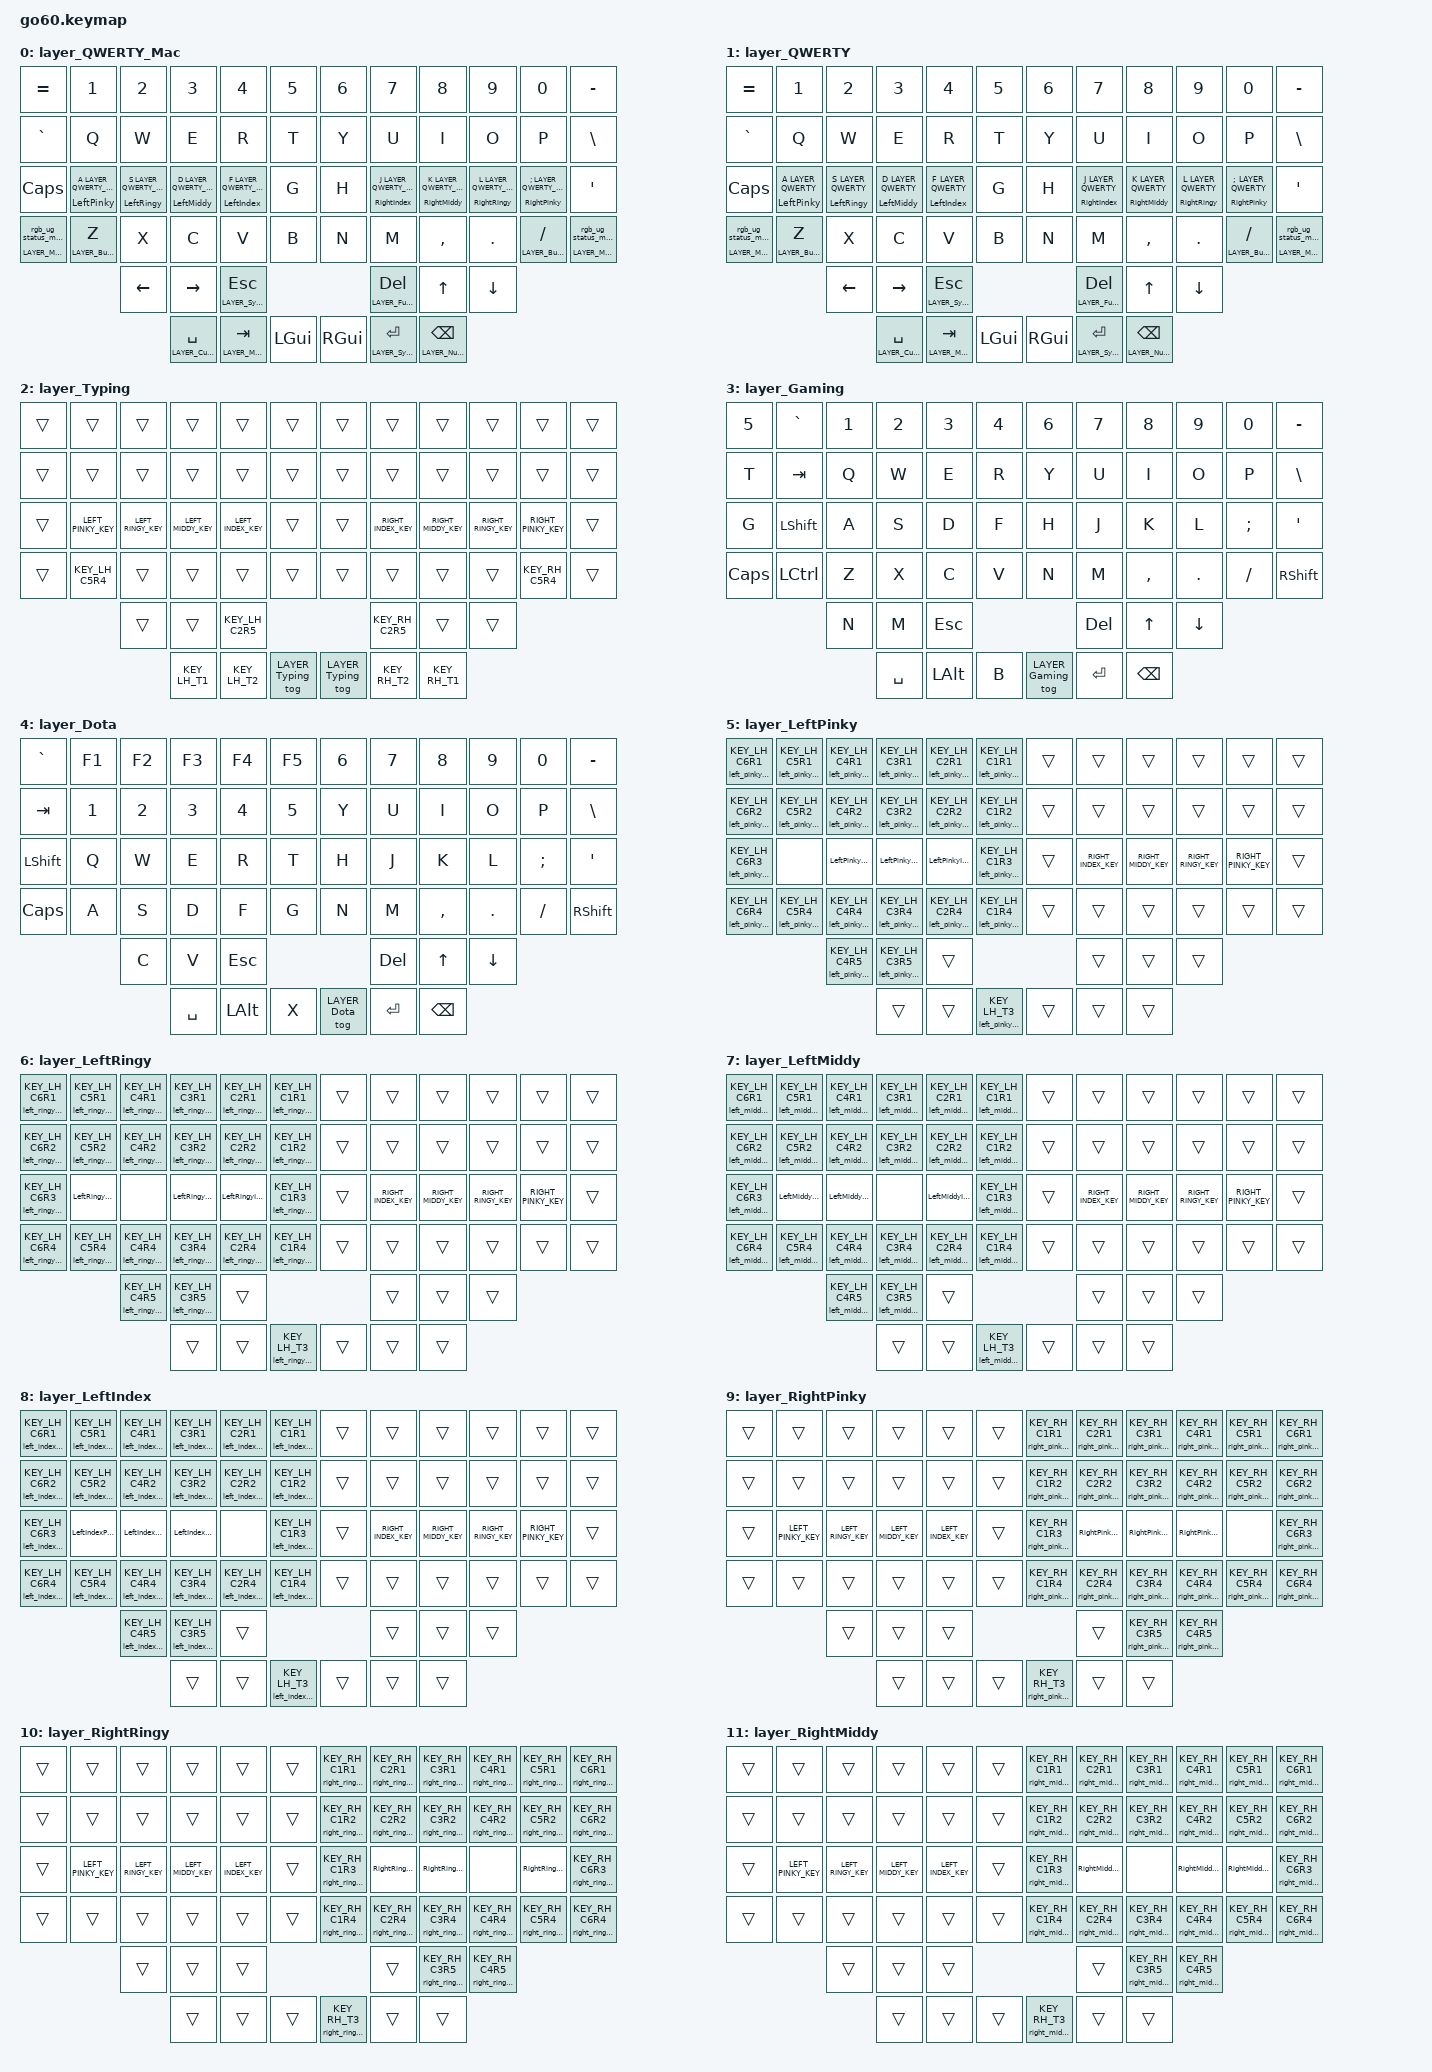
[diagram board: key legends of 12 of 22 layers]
/*
 * Copyright (c) 2020 The ZMK Contributors
 * Copyright (c) 2023 Innaworks Development Limited, trading as MoErgo
 *
 * SPDX-License-Identifier: MIT
 */

#include <behaviors.dtsi>
/* Include all behavior includes needed */
#include <dt-bindings/zmk/outputs.h>
#include <dt-bindings/zmk/keys.h>
#include <dt-bindings/zmk/bt.h>
#include <dt-bindings/zmk/rgb.h>
#include <dt-bindings/zmk/ext_power.h>
#include <dt-bindings/zmk/input_transform.h>
#include <dt-bindings/zmk/pointing.h>

#include <input/processors.dtsi>
#include <zephyr/dt-bindings/input/input-event-codes.h>

/* Helper Macros, based on https://github.com/urob/zmk-helpers/ */

#pragma once

#define ZMK_BEHAVIOR_CORE_tap_dance  \
    compatible = "zmk,behavior-tap-dance"; \
    #binding-cells = <0>

#define ZMK_BEHAVIOR(name, type, ...) \
    name: name { \
        ZMK_BEHAVIOR_CORE_ ## type; \
        __VA_ARGS__ \
    };

#define ZMK_TAP_DANCE(name, ...) \
    ZMK_BEHAVIOR(name, tap_dance, __VA_ARGS__)

#define ZMK_TD_LAYER(name, layer) \
    ZMK_TAP_DANCE(name, \
        tapping-term-ms = <200>; \
        bindings = <&mo layer>, <&to layer>; \
)

/* Environment and metadata defines */
#define KB_TYPE_GLOVE_80 1
#define KB_TYPE_GO_60    2

#define KB_TYPE          KB_TYPE_GO_60

/* Automatically generated layer name #define */
#define LAYER_QWERTY_Mac 0
#define LAYER_QWERTY 1
#define LAYER_Typing 2
#define LAYER_Gaming 3
#define LAYER_Dota 4
#define LAYER_LeftPinky 5
#define LAYER_LeftRingy 6
#define LAYER_LeftMiddy 7
#define LAYER_LeftIndex 8
#define LAYER_RightPinky 9
#define LAYER_RightRingy 10
#define LAYER_RightMiddy 11
#define LAYER_RightIndex 12
#define LAYER_System 13
#define LAYER_Cursor 14
#define LAYER_Mouse 15
#define LAYER_Symbol 16
#define LAYER_Number 17
#define LAYER_Function 18
#define LAYER_Button 19
#define LAYER_Button_Mac 20
#define LAYER_Magic 21

/* To deal with the situation where there is no Lower layer, to keep &lower happy */
#ifndef LAYER_Lower
#define LAYER_Lower 0
#endif

/* Custom Device-tree */
//////////////////////////////////////////////////////////////////////////////
//
// Per-key RGB indicators for layers & mods -- requires PR36 beta firmware:
// override "EXPERIMENTAL_RGB_LAYER" to "y" in Advanced Configuration and
// select "community.pr36.per-key-rgb" from the drop-down menu located at
// Glove80 Layout Editor > Settings > Advanced Settings > Firmware Version
//
// - https://github.com/moergo-sc/zmk/pull/36
// - https://github.com/moergo-sc/zmk/pull/30
// - https://github.com/zmkfirmware/zmk/pull/2752
// - https://dev.glove80.com/#/layout/user/c42ac32d-dc0d-4160-9ee3-fd0fc15f1725
//
//////////////////////////////////////////////////////////////////////////////

#if __has_include(<dt-bindings/zmk/rgb_colors.h>)
  //
  // Color definitions with conflict guard to prevent
  // accidental redefinition of common abbreviations.
  //
  #if defined(RED) || defined(RED_RGB) || \
      defined(COR) || defined(COR_RGB) || \
      defined(ORN) || defined(ORN_RGB) || \
      defined(GDN) || defined(GDN_RGB) || \
      defined(GOL) || defined(GOL_RGB) || \
      defined(YLW) || defined(YLW_RGB) || \
      defined(CHU) || defined(CHU_RGB) || \
      defined(GRN) || defined(GRN_RGB) || \
      defined(SPG) || defined(SPG_RGB) || \
      defined(CYN) || defined(CYN_RGB) || \
      defined(AZU) || defined(AZU_RGB) || \
      defined(TEA) || defined(TEA_RGB) || \
      defined(TUR) || defined(TUR_RGB) || \
      defined(BLU) || defined(BLU_RGB) || \
      defined(PUR) || defined(PUR_RGB) || \
      defined(MAJ) || defined(MAJ_RGB) || \
      defined(PNK) || defined(PNK_RGB) || \
      defined(WHT) || defined(WHT_RGB) || \
      defined(BLK) || defined(BLK_RGB) || \
      defined(___) || \
      defined(DUG) || defined(DUG_RGB) || \
      defined(LAC) || defined(LAC_RGB) || \
      defined(BSL) || defined(BNL) || defined(BCL) || \
      defined(SSL) || defined(SNL) || defined(SCL) || \
      defined(FST) || defined(WRP) || defined(SLO)
  #error "Naming conflict: 3-letter color abbreviation already defined!"
  #endif

  //
  // color definitions from QMK
  // https://github.com/qmk/qmk_firmware/blob/master/quantum/color.h
  //
  #define RED_RGB 0xFF0000 // #FF0000 RED      => RED (red)
  #define COR_RGB 0xFF7C4D // #FF7C4D CORAL    => COR (coral)
  #define ORN_RGB 0xFF8000 // #FF8000 ORANGE   => ORN (ornj)
  #define GDN_RGB 0xD9A521 // #D9A521 GOLDNROD => GDN (gold'nrod)
  #define GOL_RGB 0xFFD900 // #FFD900 GOLD     => GOL (gold)
  #define YLW_RGB 0xFFFF00 // #FFFF00 YELLOW   => YLW (yellow)
  #define CHU_RGB 0x80FF00 // #80FF00 CHARTRSE => CHU (chartreuse)
  #define GRN_RGB 0x00FF00 // #00FF00 GREEN    => GRN (green)
  #define SPG_RGB 0x00FF80 // #00FF80 SPRINGRN => SPG (spring green)
  #define CYN_RGB 0x00FFFF // #00FFFF CYAN     => CYN (sigh-an)
  #define AZU_RGB 0x99F5FF // #99F5FF AZURE    => AZU (a-zur)
  #define TEA_RGB 0x008080 // #008080 TEAL     => TEA (teel)
  #define TUR_RGB 0x476E6A // #476E6A TURQUOIS => TUR (turquoise)
  #define BLU_RGB 0x0000FF // #0000FF BLUE     => BLU (bloo)
  #define PUR_RGB 0x7A00FF // #7A00FF PURPLE   => PUR (purp)
  #define MAJ_RGB 0xFF00FF // #FF00FF MAGENTA  => MAJ (mah-jenta)
  #define PNK_RGB 0xFF80BF // #FF80BF PINK     => PNK (pink)
  #define WHT_RGB 0xFFFFFF // #FFFFFF WHITE    => WHT (white)
  #define BLK_RGB 0x000000 // #000000 BLACK    => BLK (blak)

  //
  // color definitions from MoErgo
  // https://github.com/moergo-sc/zmk/blob/aca523dfce9b6447ffd19d833b791d44f1f286de/app/src/rgb_underglow.c#L259-L265
  //
  #define DUG_RGB 0x00ff68 // #00ff68 DULL_GRN => DUG (dull green)
  #define LAC_RGB 0x6b1fce // #6b1fce LILAC    => LAC (lilac)

  //
  // underglow for the colors above
  //
  #define RED &ug RED_RGB
  #define COR &ug COR_RGB
  #define ORN &ug ORN_RGB
  #define GDN &ug GDN_RGB
  #define GOL &ug GOL_RGB
  #define YLW &ug YLW_RGB
  #define CHU &ug CHU_RGB
  #define GRN &ug GRN_RGB
  #define SPG &ug SPG_RGB
  #define CYN &ug CYN_RGB
  #define AZU &ug AZU_RGB
  #define TEA &ug TEA_RGB
  #define TUR &ug TUR_RGB
  #define BLU &ug BLU_RGB
  #define PUR &ug PUR_RGB
  #define MAJ &ug MAJ_RGB
  #define PNK &ug PNK_RGB
  #define WHT &ug WHT_RGB
  #define BLK &ug BLK_RGB
  #define ___ &ug BLK_RGB
  #define DUG &ug DUG_RGB
  #define LAC &ug LAC_RGB

  //
  // underglow for keyboard locks on the Base layer
  //
  #define BSL &ug_sl LAC_RGB WHT_RGB // ScrollLock COLOR_OFF COLOR_ON
  #define BNL &ug_nl LAC_RGB WHT_RGB // NumLock    COLOR_OFF COLOR_ON
  #define BCL &ug_cl BLK_RGB WHT_RGB // CapsLock   COLOR_OFF COLOR_ON

  //
  // underglow for keyboard locks on the System layer
  //
  #define SSL &ug_sl BLK_RGB WHT_RGB // ScrollLock COLOR_OFF COLOR_ON
  #define SNL &ug_nl BLK_RGB WHT_RGB // NumLock    COLOR_OFF COLOR_ON
  #define SCL &ug_cl BLK_RGB WHT_RGB // CapsLock   COLOR_OFF COLOR_ON

  //
  // colors for mouse speed scaling in Mouse layers
  //
  #define FST GOL
  #define SLO PNK
  #define WRP CHU

  // ==== PER-KEY-RGB <section begins> ====
  / {
    underglow-layer {
      compatible  = "zmk,underglow-layer";

      /*
      Template {
        bindings = <
          ___ ___ ___ ___ ___ ___                   ___ ___ ___ ___ ___ ___
          ___ ___ ___ ___ ___ ___                   ___ ___ ___ ___ ___ ___
          ___ ___ ___ ___ ___ ___                   ___ ___ ___ ___ ___ ___
          ___ ___ ___ ___ ___ ___                   ___ ___ ___ ___ ___ ___
                  ___ ___ ___                           ___ ___ ___
                              ___ ___ ___   ___ ___ ___
        >;
        layer-id = <LAYER_Template>;
      };
      */

      BaseLayer {
        bindings = <
          ___ ___ ___ ___ ___ ___                   ___ ___ ___ ___ ___ ___
          ___ ___ ___ ___ ___ ___                   ___ ___ ___ ___ ___ ___
          ___ MAJ CYN GRN YLW ___                   ___ YLW GRN CYN MAJ ___
          YLW LAC ___ ___ ___ ___                   ___ ___ ___ ___ LAC YLW
                  ___ ___ LAC                           LAC ___ ___
                              BSL BNL BCL   LAC LAC ___
        >;
        layer-id = <0>;
      };

      #ifdef LAYER_QWERTY
      QWERTY {
        bindings = <
          ___ ___ ___ ___ ___ ___                   ___ ___ ___ ___ ___ ___
          ___ ___ ___ ___ RED ___                   ___ ___ ___ ___ ___ ___
          ___ MAJ CYN GRN YLW ___                   ___ YLW GRN CYN MAJ ___
          YLW LAC ___ ___ ___ ___                   ___ ___ ___ ___ LAC YLW
                  ___ ___ RED                           LAC ___ ___
                              BSL BNL BCL   LAC LAC RED
        >;
        layer-id = <LAYER_QWERTY>;
      };
      #endif

      #ifdef LAYER_Typing
      Typing {
        bindings = <
          ___ ___ ___ ___ ___ ___                   ___ ___ ___ ___ ___ ___
          ___ ___ ___ ___ ___ ___                   ___ ___ ___ ___ ___ ___
          ___ ___ ___ ___ ___ ___                   ___ ___ ___ ___ ___ ___
          ___ ___ ___ ___ ___ ___                   ___ ___ ___ ___ ___ ___
                  ___ ___ ___                           ___ ___ ___
                              ___ ___ RED   ___ ___ RED
        >;
        layer-id = <LAYER_Typing>;
      };
      #endif

      #ifdef LAYER_Gaming
      Gaming {
        bindings = <
          GDN GDN GDN GDN GDN GDN                   ___ ___ ___ ___ ___ ___
          GDN GDN GDN AZU GDN GDN                   ___ ___ ___ ___ ___ ___
          GDN YLW AZU AZU AZU GDN                   ___ ___ ___ ___ ___ ___
          SCL GRN GDN GDN GDN GDN                   ___ ___ ___ ___ ___ ___
                  GDN GDN ___                           ___ ___ ___
                              COR CYN COR   ___ ___ RED
        >;
        layer-id = <LAYER_Gaming>;
      };
      #endif

      #ifdef LAYER_Dota
      Dota {
        bindings = <
          GDN GDN GDN GDN GDN GDN                   ___ ___ ___ ___ ___ ___
          COR GDN GDN AZU GDN GDN                   ___ ___ ___ ___ ___ ___
          YLW AZU AZU AZU AZU GDN                   ___ ___ ___ ___ ___ ___
          SCL AZU AZU AZU AZU GDN                   ___ ___ ___ ___ ___ ___
                  GDN GDN ___                           ___ ___ ___
                              COR CYN COR   ___ ___ RED
        >;
        layer-id = <LAYER_Dota>;
      };
      #endif

      #ifdef LAYER_LeftPinky
      LeftPinky {
        bindings = <
          ___ MAJ ___ ___ ___ ___                   ___ ___ ___ ___ ___ ___
          ___ ___ ___ ___ ___ ___                   ___ ___ ___ ___ ___ ___
          ___ MAJ CYN GRN YLW ___                   ___ YLW GRN CYN MAJ ___
          YLW LAC ___ ___ ___ ___                   ___ ___ ___ ___ LAC YLW
                  ___ ___ LAC                           LAC ___ ___
                              BSL BNL BCL   LAC LAC ___
        >;
        layer-id = <LAYER_LeftPinky>;
      };
      #endif

      #ifdef LAYER_LeftRingy
      LeftRingy {
        bindings = <
          ___ ___ CYN ___ ___ ___                   ___ ___ ___ ___ ___ ___
          ___ ___ ___ ___ ___ ___                   ___ ___ ___ ___ ___ ___
          ___ MAJ CYN GRN YLW ___                   ___ YLW GRN CYN MAJ ___
          YLW LAC ___ ___ ___ ___                   ___ ___ ___ ___ LAC YLW
                  ___ ___ LAC                           LAC ___ ___
                              BSL BNL BCL   LAC LAC ___
        >;
        layer-id = <LAYER_LeftRingy>;
      };
      #endif

      #ifdef LAYER_LeftMiddy
      LeftMiddy {
        bindings = <
          ___ ___ ___ GRN ___ ___                   ___ ___ ___ ___ ___ ___
          ___ ___ ___ ___ ___ ___                   ___ ___ ___ ___ ___ ___
          ___ MAJ CYN GRN YLW ___                   ___ YLW GRN CYN MAJ ___
          YLW LAC ___ ___ ___ ___                   ___ ___ ___ ___ LAC YLW
                  ___ ___ LAC                           LAC ___ ___
                              BSL BNL BCL   LAC LAC ___
        >;
        layer-id = <LAYER_LeftMiddy>;
      };
      #endif

      #ifdef LAYER_LeftIndex
      LeftIndex {
        bindings = <
          ___ ___ ___ ___ YLW ___                   ___ ___ ___ ___ ___ ___
          ___ ___ ___ ___ ___ ___                   ___ ___ ___ ___ ___ ___
          ___ MAJ CYN GRN YLW ___                   ___ YLW GRN CYN MAJ ___
          YLW LAC ___ ___ ___ ___                   ___ ___ ___ ___ LAC YLW
                  ___ ___ LAC                           LAC ___ ___
                              BSL BNL BCL   LAC LAC ___
        >;
        layer-id = <LAYER_LeftIndex>;
      };
      #endif

      #ifdef LAYER_RightIndex
      RightIndex {
        bindings = <
          ___ ___ ___ ___ ___ ___                   ___ YLW ___ ___ ___ ___
          ___ ___ ___ ___ ___ ___                   ___ ___ ___ ___ ___ ___
          ___ MAJ CYN GRN YLW ___                   ___ YLW GRN CYN MAJ ___
          YLW LAC ___ ___ ___ ___                   ___ ___ ___ ___ LAC YLW
                  ___ ___ LAC                           LAC ___ ___
                              BSL BNL BCL   LAC LAC ___
        >;
        layer-id = <LAYER_RightIndex>;
      };
      #endif

      #ifdef LAYER_RightMiddy
      RightMiddy {
        bindings = <
          ___ ___ ___ ___ ___ ___                   ___ ___ GRN ___ ___ ___
          ___ ___ ___ ___ ___ ___                   ___ ___ ___ ___ ___ ___
          ___ MAJ CYN GRN YLW ___                   ___ YLW GRN CYN MAJ ___
          YLW LAC ___ ___ ___ ___                   ___ ___ ___ ___ LAC YLW
                  ___ ___ LAC                           LAC ___ ___
                              BSL BNL BCL   LAC LAC ___
        >;
        layer-id = <LAYER_RightMiddy>;
      };
      #endif

      #ifdef LAYER_RightRingy
      RightRingy {
        bindings = <
          ___ ___ ___ ___ ___ ___                   ___ ___ ___ CYN ___ ___
          ___ ___ ___ ___ ___ ___                   ___ ___ ___ ___ ___ ___
          ___ MAJ CYN GRN YLW ___                   ___ YLW GRN CYN MAJ ___
          YLW LAC ___ ___ ___ ___                   ___ ___ ___ ___ LAC YLW
                  ___ ___ LAC                           LAC ___ ___
                              BSL BNL BCL   LAC LAC ___
        >;
        layer-id = <LAYER_RightRingy>;
      };
      #endif

      #ifdef LAYER_RightPinky
      RightPinky {
        bindings = <
          ___ ___ ___ ___ ___ ___                   ___ ___ ___ ___ MAJ ___
          ___ ___ ___ ___ ___ ___                   ___ ___ ___ ___ ___ ___
          ___ MAJ CYN GRN YLW ___                   ___ YLW GRN CYN MAJ ___
          YLW LAC ___ ___ ___ ___                   ___ ___ ___ ___ LAC YLW
                  ___ ___ LAC                           LAC ___ ___
                              BSL BNL BCL   LAC LAC ___
        >;
        layer-id = <LAYER_RightPinky>;
      };
      #endif

      #ifdef LAYER_System
      System {
        bindings = <
          ___ ___ ___ ___ ___ ___                   ___ ___ ___ ___ ___ ___
          ___ PUR COR COR COR PUR                   PNK PNK PNK PNK PNK ___
          ___ MAJ CYN GRN YLW ___                   AZU AZU AZU AZU PNK ___
          ___ SPG SPG COR COR ___                   BLU BLU BLU BLU BLU ___
                  ___ ___ RED                           AZU ___ ___
                              ___ ___ ___   AZU AZU ___
        >;
        layer-id = <LAYER_System>;
      };
      #endif

      #ifdef LAYER_Cursor
      Cursor {
        bindings = <
          ___ ___ ___ ___ ___ ___                   ___ ___ ___ ___ ___ ___
          ___ ___ COR ___ COR ___                   ___ ___ ___ ___ ___ ___
          ___ MAJ CYN GRN YLW ___                   AZU AZU AZU AZU SPG ___
          ___ SPG SPG COR COR ___                   SPG SPG SPG SPG SPG ___
                  ___ ___ ___                           SPG ___ ___
                              RED ___ ___   SPG SPG ___
        >;
        layer-id = <LAYER_Cursor>;
      };
      #endif

      #ifdef LAYER_Mouse
      Mouse {
        bindings = <
          ___ ___ ___ ___ ___ ___                   ___ ___ ___ ___ ___ ___
          ___ ___ COR COR COR ___                   ___ ___ ___ ___ ___ ___
          ___ MAJ CYN GRN YLW ___                   AZU AZU AZU AZU AZU ___
          ___ SPG SPG COR COR ___                   AZU AZU AZU AZU AZU ___
                  ___ ___ ___                           AZU ___ ___
                              ___ RED ___   AZU AZU ___
        >;
        layer-id = <LAYER_Mouse>;
      };
      #endif

      #ifdef LAYER_Function
      Function {
        bindings = <
          ___ ___ ___ ___ ___ ___                   ___ ___ ___ ___ ___ ___
          ___ PNK PNK PNK PNK GDN                   PUR COR COR COR PUR ___
          ___ PNK PNK PNK PNK SSL                   ___ YLW GRN CYN MAJ ___
          ___ PNK PNK PNK PNK GDN                   ___ COR COR SPG SPG ___
                  ___ ___ GDN                           RED ___ ___
                              SPG SPG ___   ___ ___ ___
        >;
        layer-id = <LAYER_Function>;
      };
      #endif

      #ifdef LAYER_Number
      Number {
        bindings = <
          ___ ___ ___ ___ ___ ___                   ___ ___ ___ ___ ___ ___
          ___ SPG GOL GOL GOL SPG                   ___ COR ___ COR ___ ___
          ___ SPG GOL GOL GOL SPG                   ___ YLW GRN CYN MAJ ___
          ___ SPG GOL GOL GOL SPG                   ___ COR COR SPG SPG ___
                  ___ ___ SPG                           ___ ___ ___
                              SPG SPG ___   RED ___ ___
        >;
        layer-id = <LAYER_Number>;
      };
      #endif

      #ifdef LAYER_Symbol
      Symbol {
        bindings = <
          ___ ___ ___ ___ ___ ___                   ___ ___ ___ ___ ___ ___
          ___ SPG SPG SPG SPG SPG                   ___ COR COR COR ___ ___
          ___ SPG SPG SPG SPG SPG                   ___ YLW GRN CYN MAJ ___
          ___ SPG SPG SPG SPG SPG                   ___ COR COR SPG SPG ___
                  ___ ___ SPG                           ___ ___ ___
                              SPG SPG ___   ___ RED ___
        >;
        layer-id = <LAYER_Symbol>;
      };
      #endif

      #ifdef LAYER_Button
      Button {
        bindings = <
          ___ ___ ___ ___ ___ ___                   ___ ___ ___ ___ ___ ___
          ___ ___ GDN ORN ORN ORN                   ORN ORN ORN ORN ___ ___
          ___ MAJ CYN GRN YLW ORN                   ORN YLW GRN CYN MAJ ___
          ___ ORN ORN ORN ORN ORN                   ORN ORN ORN ORN ORN ___
                  ___ ___ COR                           COR ___ ___
                              COR COR ___   COR COR ___
        >;
        layer-id = <LAYER_Button>;
      };
      #endif

      #ifdef LAYER_Button_Mac
      Button_Mac {
        bindings = <
          RED ___ ___ ___ ___ ___                   ___ ___ ___ ___ ___ RED
          ___ ___ GDN ORN ORN ORN                   ORN ORN ORN ORN ___ ___
          ___ MAJ CYN GRN YLW ORN                   ORN YLW GRN CYN MAJ ___
          ___ ORN ORN ORN ORN ORN                   ORN ORN ORN ORN ORN ___
                  ___ ___ COR                           COR ___ ___
                              COR COR ___   COR COR ___
        >;
        layer-id = <LAYER_Button_Mac>;
      };
      #endif
    };
  };
  // ==== PER-KEY-RGB <section ends> =====

  #undef RED
  #undef RED_RGB
  #undef COR
  #undef COR_RGB
  #undef ORN
  #undef ORN_RGB
  #undef GDN
  #undef GDN_RGB
  #undef GOL
  #undef GOL_RGB
  #undef YLW
  #undef YLW_RGB
  #undef CHU
  #undef CHU_RGB
  #undef GRN
  #undef GRN_RGB
  #undef SPG
  #undef SPG_RGB
  #undef CYN
  #undef CYN_RGB
  #undef AZU
  #undef AZU_RGB
  #undef TEA
  #undef TEA_RGB
  #undef TUR
  #undef TUR_RGB
  #undef BLU
  #undef BLU_RGB
  #undef PUR
  #undef PUR_RGB
  #undef MAJ
  #undef MAJ_RGB
  #undef PNK
  #undef PNK_RGB
  #undef WHT
  #undef WHT_RGB
  #undef BLK
  #undef BLK_RGB
  #undef ___
  #undef DUG
  #undef DUG_RGB
  #undef LAC
  #undef LAC_RGB

  #undef BSL
  #undef BNL
  #undef BCL

  #undef SSL
  #undef SNL
  #undef SCL

  #undef FST
  #undef WRP
  #undef SLO
#endif

/* Glove80 system behavior & macros */
/ {
    input_processors {
        zip_click_to_right_click_mapper: zip_click_to_right_click_mapper {
            compatible = "zmk,input-processor-code-mapper";
            #input-processor-cells = <0>;
            type = <INPUT_EV_KEY>;
            map = <INPUT_BTN_0 INPUT_BTN_1>;
        };
    };

    behaviors {
        ZMK_TD_LAYER(lower, LAYER_Lower)

        magic: magic {
            compatible = "zmk,behavior-hold-tap";
            label = "MAGIC_HOLD_TAP";
            #binding-cells = <2>;
            flavor = "tap-preferred";
            tapping-term-ms = <200>;
            bindings = <&mo>, <&rgb_ug_status_macro>;
        };
    };

    macros {
        rgb_ug_status_macro: rgb_ug_status_macro {
            label = "RGB_UG_STATUS";
            compatible = "zmk,behavior-macro";
            #binding-cells = <0>;
            bindings
                = <&rgb_ug RGB_STATUS>;
        };
    };
};


/ {
#ifdef BT_DISC_CMD
    behaviors {
        bt_0: bt_0 {
            compatible = "zmk,behavior-tap-dance";
            label = "BT_0";
            #binding-cells = <0>;
            tapping-term-ms = <200>;
            bindings = <&bt_select_0>, <&bt BT_DISC 0>;
        };
        bt_1: bt_1 {
            compatible = "zmk,behavior-tap-dance";
            label = "BT_1";
            #binding-cells = <0>;
            tapping-term-ms = <200>;
            bindings = <&bt_select_1>, <&bt BT_DISC 1>;
        };
        bt_2: bt_2 {
            compatible = "zmk,behavior-tap-dance";
            label = "BT_2";
            #binding-cells = <0>;
            tapping-term-ms = <200>;
            bindings = <&bt_select_2>, <&bt BT_DISC 2>;
        };
        bt_3: bt_3 {
            compatible = "zmk,behavior-tap-dance";
            label = "BT_3";
            #binding-cells = <0>;
            tapping-term-ms = <200>;
            bindings = <&bt_select_3>, <&bt BT_DISC 3>;
        };
    };
    macros {
        bt_select_0: bt_select_0 {
            label = "BT_SELECT_0";
            compatible = "zmk,behavior-macro";
            #binding-cells = <0>;
            bindings
                = <&out OUT_BLE>,
                  <&bt BT_SEL 0>;
        };
        bt_select_1: bt_select_1 {
            label = "BT_SELECT_1";
            compatible = "zmk,behavior-macro";
            #binding-cells = <0>;
            bindings
                = <&out OUT_BLE>,
                  <&bt BT_SEL 1>;
        };
        bt_select_2: bt_select_2 {
            label = "BT_SELECT_2";
            compatible = "zmk,behavior-macro";
            #binding-cells = <0>;
            bindings
                = <&out OUT_BLE>,
                  <&bt BT_SEL 2>;
        };
        bt_select_3: bt_select_3 {
            label = "BT_SELECT_3";
            compatible = "zmk,behavior-macro";
            #binding-cells = <0>;
            bindings
                = <&out OUT_BLE>,
                  <&bt BT_SEL 3>;
        };
    };
#else
    macros {
        bt_0: bt_0 {
            label = "BT_0";
            compatible = "zmk,behavior-macro";
            #binding-cells = <0>;
            bindings
                = <&out OUT_BLE>,
                  <&bt BT_SEL 0>;
        };
        bt_1: bt_1 {
            label = "BT_1";
            compatible = "zmk,behavior-macro";
            #binding-cells = <0>;
            bindings
                = <&out OUT_BLE>,
                  <&bt BT_SEL 1>;
        };
        bt_2: bt_2 {
            label = "BT_2";
            compatible = "zmk,behavior-macro";
            #binding-cells = <0>;
            bindings
                = <&out OUT_BLE>,
                  <&bt BT_SEL 2>;
        };
        bt_3: bt_3 {
            label = "BT_3";
            compatible = "zmk,behavior-macro";
            #binding-cells = <0>;
            bindings
                = <&out OUT_BLE>,
                  <&bt BT_SEL 3>;
        };
    };
#endif
};

/ {
    behaviors {
    };
};

/* Key positions */
#define POS_LH_C6R1 0
#define POS_LH_C5R1 1
#define POS_LH_C4R1 2
#define POS_LH_C3R1 3
#define POS_LH_C2R1 4
#define POS_LH_C1R1 5
#define POS_RH_C1R1 6
#define POS_RH_C2R1 7
#define POS_RH_C3R1 8
#define POS_RH_C4R1 9
#define POS_RH_C5R1 10
#define POS_RH_C6R1 11
#define POS_LH_C6R2 12
#define POS_LH_C5R2 13
#define POS_LH_C4R2 14
#define POS_LH_C3R2 15
#define POS_LH_C2R2 16
#define POS_LH_C1R2 17
#define POS_RH_C1R2 18
#define POS_RH_C2R2 19
#define POS_RH_C3R2 20
#define POS_RH_C4R2 21
#define POS_RH_C5R2 22
#define POS_RH_C6R2 23
#define POS_LH_C6R3 24
#define POS_LH_C5R3 25
#define POS_LH_C4R3 26
#define POS_LH_C3R3 27
#define POS_LH_C2R3 28
#define POS_LH_C1R3 29
#define POS_RH_C1R3 30
#define POS_RH_C2R3 31
#define POS_RH_C3R3 32
#define POS_RH_C4R3 33
#define POS_RH_C5R3 34
#define POS_RH_C6R3 35
#define POS_LH_C6R4 36
#define POS_LH_C5R4 37
#define POS_LH_C4R4 38
#define POS_LH_C3R4 39
#define POS_LH_C2R4 40
#define POS_LH_C1R4 41
#define POS_RH_C1R4 42
#define POS_RH_C2R4 43
#define POS_RH_C3R4 44
#define POS_RH_C4R4 45
#define POS_RH_C5R4 46
#define POS_RH_C6R4 47
#define POS_LH_C4R5 48
#define POS_LH_C3R5 49
#define POS_LH_C2R5 50
#define POS_RH_C2R5 51
#define POS_RH_C3R5 52
#define POS_RH_C4R5 53
#define POS_LH_T1 54
#define POS_LH_T2 55
#define POS_LH_T3 56
#define POS_RH_T3 57
#define POS_RH_T2 58
#define POS_RH_T1 59

/* Custom Defined Behaviors */
/ {
// NOTE: Use the many #define settings below to customize this keymap!
#define DIFFICULTY_LEVEL  0  // 0:custom, 1:easy -> 5:hard (see below)
#define ENFORCE_BILATERAL    // cancels single-handed home row mod+tap
#define SPACE_FORGIVENESS    // allow lingering taps on the space bar
// TIP: Add more setting overrides here instead of editing them below.

//////////////////////////////////////////////////////////////////////////////
//
// Sunaku's Keymap v41 -- "Glorious Engrammer"
// - https://github.com/sunaku/glove80-keymaps
//
//////////////////////////////////////////////////////////////////////////////

//
// OPERATING_SYSTEM defines which operating system you intend to use
// with this keymap, because shortcuts vary across operating systems.
//
// - https://zmk.dev/docs/codes
// - https://en.wikipedia.org/wiki/Table_of_keyboard_shortcuts
//
// This setting also affects the UNICODE() function defined below, as
// each OS has different shortcuts for typing Unicode hex characters.
//
// NOTE: You may need to enable Unicode hexadecimal input in your OS:
// - (macOS) https://uknowit.uwgb.edu/page.php?id=22623
//     and   https://github.com/ldanet/unicode-hex-input-fix
// - (Linux) https://help.ubuntu.com/stable/ubuntu-help/tips-specialchars.html.en#ctrlshiftu
// - (Windows) https://github.com/samhocevar/wincompose
//
// Specifically, Windows users should be running the WinCompose tool,
// which lets you type Unicode characters via hexadecimal codepoints.
//
// Windows/Linux Def
#define _C      LC
#define _REDO   _C(Y)
#define _UNDO   _C(Z)
#define _CUT    _C(X)
#define _COPY   _C(C)
#define _PASTE  _C(V)
#define _FIND   _C(F)
// Mac Def
#define _C_Mac      LG
#define _REDO_Mac   _C_Mac(LS(Z))
#define _HOME_Mac   _C_Mac(LEFT)
#define _END_Mac    _C_Mac(RIGHT)
#define _UNDO_Mac   _C_Mac(Z)
#define _CUT_Mac    _C_Mac(X)
#define _COPY_Mac   _C_Mac(C)
#define _PASTE_Mac  _C_Mac(V)
#define _FIND_Mac   _C_Mac(F)
#define _PSCRN_Mac  _C_Mac(LS(N4))

//
// Keymap specific knowledge of the base layer's alpha + ZMK layout
//
#define KEY_LH_C6R1 EQUAL
#define KEY_LH_C5R1 N1
#define KEY_LH_C4R1 N2
#define KEY_LH_C3R1 N3
#define KEY_LH_C2R1 N4
#define KEY_LH_C1R1 N5
#define KEY_RH_C1R1 N6
#define KEY_RH_C2R1 N7
#define KEY_RH_C3R1 N8
#define KEY_RH_C4R1 N9
#define KEY_RH_C5R1 N0
#define KEY_RH_C6R1 MINUS
#define KEY_LH_C6R2 GRAVE
#define KEY_LH_C5R2 Q
#define KEY_LH_C4R2 W
#define KEY_LH_C3R2 E
#define KEY_LH_C2R2 R
#define KEY_LH_C1R2 T
#define KEY_RH_C1R2 Y
#define KEY_RH_C2R2 U
#define KEY_RH_C3R2 I
#define KEY_RH_C4R2 O
#define KEY_RH_C5R2 P
#define KEY_RH_C6R2 BSLH
#define KEY_LH_C6R3 CAPS
#define KEY_LH_C5R3 A
#define KEY_LH_C4R3 S
#define KEY_LH_C3R3 D
#define KEY_LH_C2R3 F
#define KEY_LH_C1R3 G
#define KEY_RH_C1R3 H
#define KEY_RH_C2R3 J
#define KEY_RH_C3R3 K
#define KEY_RH_C4R3 L
#define KEY_RH_C5R3 SEMI
#define KEY_RH_C6R3 SQT
#define KEY_LH_C6R4 LSFT
#define KEY_LH_C5R4 Z
#define KEY_LH_C4R4 X
#define KEY_LH_C3R4 C
#define KEY_LH_C2R4 V
#define KEY_LH_C1R4 B
#define KEY_RH_C1R4 N
#define KEY_RH_C2R4 M
#define KEY_RH_C3R4 COMMA
#define KEY_RH_C4R4 DOT
#define KEY_RH_C5R4 FSLH
#define KEY_RH_C6R4 RSFT
#define KEY_LH_C4R5 LEFT
#define KEY_LH_C3R5 RIGHT
#define KEY_LH_C2R5 ESC
#define KEY_RH_C2R5 DELETE
#define KEY_RH_C3R5 UP
#define KEY_RH_C4R5 DOWN
#define KEY_LH_T1 SPACE
#define KEY_LH_T2 TAB
#define KEY_LH_T3 LALT
#define KEY_RH_T3 RALT
#define KEY_RH_T2 ENTER
#define KEY_RH_T1 BSPC

combos {};

behaviors {

  //////////////////////////////////////////////////////////////////////////
  //
  // Miryoku layers and home row mods (ported from my QMK endgame)
  // - https://sunaku.github.io/home-row-mods.html#porting-to-zmk
  // - https://github.com/urob/zmk-config#timeless-homerow-mods
  //
  //////////////////////////////////////////////////////////////////////////

  //
  // DIFFICULTY_LEVEL specifies your level of expertise with this keymap.
  // It's meant to help newcomers gradually work their way up to mastery.
  //
  // #define DIFFICULTY_LEVEL 1 // novice (500ms)
  // #define DIFFICULTY_LEVEL 2 // slower (400ms)
  // #define DIFFICULTY_LEVEL 3 // normal (300ms)
  // #define DIFFICULTY_LEVEL 4 // faster (200ms)
  // #define DIFFICULTY_LEVEL 5 // expert (100ms)
  //
  // You can disable this setting by omitting it or assigning a `0` zero,
  // in which case it will default to my personal set of time thresholds.
  //
  // #define DIFFICULTY_LEVEL 0 // sunaku (150ms)
  //
  // No matter what difficulty level you choose, you can always override
  // any settings in this keymap at the beginning of this configuration.
  //
  #ifdef DIFFICULTY_LEVEL
    #if DIFFICULTY_LEVEL > 0 && DIFFICULTY_LEVEL < 6
      #ifndef TAPPING_RESOLUTION
        #define TAPPING_RESOLUTION ((6 - DIFFICULTY_LEVEL) * 100)
      #endif
    #endif
  #endif

  //
  // TAPPING_RESOLUTION specifies the maximum speed at which the keyboard
  // confuses your taps as being holds when you type on home row mod keys.
  // When you lower this value, the same confusion should still occur; but
  // when you raise this value, you should be able to type normally again.
  //
  #ifndef TAPPING_RESOLUTION
  #define TAPPING_RESOLUTION 150
  #endif

  //
  // ENFORCE_BILATERAL cancels out single-handed home row mods activation by
  // releasing any currently pressed mods and replacing them with plain taps.
  //
  // NOTE: You may still encounter "flashing mods" where an operating system
  // action is triggered by the release of mods, such as LGUI which launches
  // the Windows Start Menu and LALT which opens the Microsoft Office Ribbon.
  //
  //#define ENFORCE_BILATERAL

  //
  // SPACE_FORGIVENESS taps when the symbol layer access key is merely held
  // and released, without any symbol been tapped while the access was held.
  // For example, suppose you hold the symbol layer key and, before pressing
  // another key, you suddenly decide that you don't want the layer anymore:
  //
  // <1> If this setting is enabled, the underlying tap behavior is triggered
  //     to type a single character when you release that layer access key.
  //
  // <2> Otherwise, nothing happens when you release that layer access key.
  //
  // NOTE: This setting interferes with (and effectively disables) per-key
  // RGB indicators (PR30) for layers accessed via thumb layer access keys.
  //
  //#define SPACE_FORGIVENESS

  //
  // The *_FINGER_MOD specify which modifiers are used by home row mod keys.
  // Here, we use Miryoku's "GACS" (Win, Alt, Ctrl, Shift) order by default.
  //
  #ifndef PINKY_FINGER_MOD
  #define PINKY_FINGER_MOD LGUI
  #endif
  #ifndef RINGY_FINGER_MOD
  #define RINGY_FINGER_MOD LALT
  #endif
  #ifndef MIDDY_FINGER_MOD
  #define MIDDY_FINGER_MOD LCTL
  #endif
  #ifndef INDEX_FINGER_MOD
  #define INDEX_FINGER_MOD LSFT
  #endif
  //
  // The following settings let you configure mods individually, per finger:
  //
  #ifndef LEFT_PINKY_MOD
  #define LEFT_PINKY_MOD PINKY_FINGER_MOD
  #endif
  #ifndef RIGHT_PINKY_MOD
  #define RIGHT_PINKY_MOD PINKY_FINGER_MOD
  #endif
  #ifndef LEFT_RINGY_MOD
  #define LEFT_RINGY_MOD RINGY_FINGER_MOD
  #endif
  #ifndef RIGHT_RINGY_MOD
  #define RIGHT_RINGY_MOD RINGY_FINGER_MOD
  #endif
  #ifndef LEFT_MIDDY_MOD
  #define LEFT_MIDDY_MOD MIDDY_FINGER_MOD
  #endif
  #ifndef RIGHT_MIDDY_MOD
  #define RIGHT_MIDDY_MOD MIDDY_FINGER_MOD
  #endif
  #ifndef LEFT_INDEX_MOD
  #define LEFT_INDEX_MOD INDEX_FINGER_MOD
  #endif
  #ifndef RIGHT_INDEX_MOD
  #define RIGHT_INDEX_MOD INDEX_FINGER_MOD
  #endif

  //
  // HOMEY_HOLDING_TYPE defines the flavor of ZMK hold-tap behavior to use
  // for the pinky, ring, and middle fingers (which are assigned to Super,
  // Alt, and Ctrl respectively in the Miryoku system) on home row keys.
  //
  #ifndef HOMEY_HOLDING_TYPE
  #define HOMEY_HOLDING_TYPE "tap-preferred"
  #endif

  //
  // HOMEY_HOLDING_TIME defines how long you need to hold (milliseconds)
  // home row mod keys in order to send their modifiers to the computer
  // (i.e. "register" them) for mod-click mouse usage (e.g. Ctrl-Click).
  //
  #ifndef HOMEY_HOLDING_TIME
  #define HOMEY_HOLDING_TIME (TAPPING_RESOLUTION + 90)
  #endif
  #ifndef INDEX_HOLDING_TIME
  #define INDEX_HOLDING_TIME (TAPPING_RESOLUTION + 20)
  #endif
  #ifndef MIDDY_HOLDING_TIME
  #define MIDDY_HOLDING_TIME (TAPPING_RESOLUTION + 60)
  #endif
  #ifndef RINGY_HOLDING_TIME
  #define RINGY_HOLDING_TIME (TAPPING_RESOLUTION + 90)
  #endif
  #ifndef PINKY_HOLDING_TIME
  #define PINKY_HOLDING_TIME (TAPPING_RESOLUTION + 110)
  #endif

  //
  // HOMEY_STREAK_DECAY defines how long you need to wait (milliseconds)
  // after typing before you can use home row mods again.  It prevents
  // unintended activation of home row mods when you're actively typing.
  //
  #ifndef HOMEY_STREAK_DECAY
  #define HOMEY_STREAK_DECAY TAPPING_RESOLUTION
  #endif

  //
  // HOMEY_REPEAT_DECAY defines how much time you have left (milliseconds)
  // after tapping a key to hold it again in order to make it auto-repeat.
  //
  #ifndef HOMEY_REPEAT_DECAY
  #define HOMEY_REPEAT_DECAY (TAPPING_RESOLUTION + 150)
  #endif // "tap then hold" for key auto-repeat

  //
  // CHORD_HOLDING_TYPE defines the flavor of ZMK hold-tap behavior to use
  // for chorded home row mods (secondary keypresses in multi-mod chords).
  //
  #ifndef CHORD_HOLDING_TYPE
  #define CHORD_HOLDING_TYPE HOMEY_HOLDING_TYPE
  #endif

  //
  // CHORD_HOLDING_TIME defines how long you need to hold (milliseconds)
  // home row mod keys in order to send their modifiers to the computer
  // (i.e. "register" them) for mod-click mouse usage (e.g. Ctrl-Click).
  // This is specifically for secondary keypresses in multi-mod chords.
  //
  #ifndef CHORD_HOLDING_TIME
  #define CHORD_HOLDING_TIME TAPPING_RESOLUTION
  #endif

  //
  // CHORD_STREAK_DECAY defines how long you need to wait (milliseconds)
  // after typing before you can use home row mods again.  It prevents
  // unintended activation of home row mods when you're actively typing
  // This is specifically for secondary keypresses in multi-mod chords.
  //
  #ifndef CHORD_STREAK_DECAY
  #define CHORD_STREAK_DECAY HOMEY_STREAK_DECAY
  #endif

  //
  // CHORD_REPEAT_DECAY defines how much time you have left (milliseconds)
  // after tapping a key to hold it again in order to make it auto-repeat.
  // This is specifically for secondary keypresses in multi-mod chords.
  //
  #ifndef CHORD_REPEAT_DECAY
  #define CHORD_REPEAT_DECAY HOMEY_REPEAT_DECAY
  #endif

  //
  // INDEX_HOLDING_TYPE defines the flavor of ZMK hold-tap behavior to use
  // for index fingers (which Miryoku assigns to Shift) on home row keys.
  //
  // NOTE: The "tap-preferred" flavor of ZMK hold-tap for index finger keys
  // allows faster activation of the Shift modifier (without having to wait
  // for the modified key to be released as the "balanced" flavor requires).
  //
  #ifndef INDEX_HOLDING_TYPE
  #define INDEX_HOLDING_TYPE "tap-preferred"
  #endif

  //
  // INDEX_STREAK_DECAY defines how long you need to wait (milliseconds)
  // after typing before you can use home row mods again.  It prevents
  // unintended activation of home row mods when you're actively typing.
  //
  #ifndef INDEX_STREAK_DECAY
  #define INDEX_STREAK_DECAY (TAPPING_RESOLUTION - 50)
  #endif

  //
  // INDEX_REPEAT_DECAY defines how much time you have left (milliseconds)
  // after tapping a key to hold it again in order to make it auto-repeat.
  //
  #ifndef INDEX_REPEAT_DECAY
  #define INDEX_REPEAT_DECAY (TAPPING_RESOLUTION + 150)
  #endif // "tap then hold" for key auto-repeat

  //
  // PLAIN_HOLDING_TYPE defines the flavor of ZMK hold-tap behavior to use
  // for index fingers (which Miryoku assigns to Shift) on home row keys.
  //
  // NOTE: The "tap-preferred" flavor of ZMK hold-tap for index finger keys
  // allows faster activation of the Shift modifier (without having to wait
  // for the modified key to be released as the "balanced" flavor requires).
  //
  #ifndef PLAIN_HOLDING_TYPE
  #define PLAIN_HOLDING_TYPE INDEX_HOLDING_TYPE
  #endif

  //
  // PLAIN_HOLDING_TIME defines how long you need to hold (milliseconds)
  // index finger keys in order to send their modifiers to the computer
  // (i.e. "register" them) for mod-click mouse usage (e.g. Shift-Click).
  //
  #ifndef PLAIN_HOLDING_TIME
  #define PLAIN_HOLDING_TIME (TAPPING_RESOLUTION + 50)
  #endif

  //
  // PLAIN_STREAK_DECAY defines how long you need to wait (milliseconds)
  // after typing before you can use home row mods again.  It prevents
  // unintended activation of home row mods when you're actively typing.
  //
  #ifndef PLAIN_STREAK_DECAY
  #define PLAIN_STREAK_DECAY HOMEY_STREAK_DECAY
  #endif

  //
  // PLAIN_REPEAT_DECAY defines how much time you have left (milliseconds)
  // after tapping a key to hold it again in order to make it auto-repeat.
  //
  #ifndef PLAIN_REPEAT_DECAY
  #define PLAIN_REPEAT_DECAY (TAPPING_RESOLUTION + 150)
  #endif // "tap then hold" for key auto-repeat

  //
  // THUMB_HOLDING_TYPE defines the flavor of ZMK hold-tap behavior to use
  // for the thumbs (which are assigned to 6 layers in the Miryoku system).
  //
  // NOTE: The "balanced" flavor of ZMK hold-tap provides instant modifier
  // activation for the symbol layer (if the tapped symbol key is released
  // while the thumb layer key is still held down) for quicker programming.
  //
  #ifndef THUMB_HOLDING_TYPE
  #define THUMB_HOLDING_TYPE "balanced"
  #endif

  //
  // THUMB_HOLDING_TIME defines how long you need to hold (milliseconds)
  // a thumb key to activate a layer.  Shorter holds are treated as taps.
  //
  #ifndef THUMB_HOLDING_TIME
  #define THUMB_HOLDING_TIME (TAPPING_RESOLUTION + 50)
  #endif

  //
  // THUMB_REPEAT_DECAY defines how much time you have left (milliseconds)
  // after tapping a key to hold it again in order to make it auto-repeat.
  //
  #ifndef THUMB_REPEAT_DECAY
  #define THUMB_REPEAT_DECAY (TAPPING_RESOLUTION + 150)
  #endif // "tap then hold" for key auto-repeat

  //
  // SPACE_HOLDING_TYPE defines the flavor of ZMK hold-tap behavior to use
  // for spacebar (assigned to the right thumb's home position by default).
  //
  #ifndef SPACE_HOLDING_TYPE
  #define SPACE_HOLDING_TYPE THUMB_HOLDING_TYPE
  #endif

  //
  // SPACE_HOLDING_TIME defines how long you need to hold (milliseconds)
  // the space thumb key to activate.  Shorter holds are treated as taps.
  //
  #ifndef SPACE_HOLDING_TIME
  #define SPACE_HOLDING_TIME (TAPPING_RESOLUTION + 20)
  #endif

  //
  // SPACE_REPEAT_DECAY defines how much time you have left (milliseconds)
  // after tapping a key to hold it again in order to make it auto-repeat.
  //
  #ifndef SPACE_REPEAT_DECAY
  #define SPACE_REPEAT_DECAY TAPPING_RESOLUTION
  #endif

  //
  // Go60 key positions index for positional hold-tap
  // - https://discord.com/channels/877392805654306816/937645688244826154/1066713913351221248
  // - https://media.discordapp.net/attachments/937645688244826154/1066713913133121556/image.png
  //
  // |-------------------------|-------------------------|
  // | LEFT_HAND_KEYS          |         RIGHT_HAND_KEYS |
  // |                         |                         |
  // |  0  1  2  3  4  5       |        6  7  8  9 10 11 |
  // | 12 13 14 15 16 17       |       18 19 20 21 22 23 |
  // | 24 25 26 27 28 29       |       30 31 32 33 34 35 |
  // | 36 37 38 39 40 41       |       42 43 44 45 46 47 |
  // |       48 49 50          |          51 52 53       |
  // |                54 55 56 | 57 58 59                |
  // |-------------------------|-------------------------|
  //
  #define LEFT_HAND_KEYS       \
        0  1  2  3  4  5       \
       12 13 14 15 16 17       \
       24 25 26 27 28 29       \
       36 37 38 39 40 41       \
             48 49 50
  #define RIGHT_HAND_KEYS      \
                                        6  7  8  9 10 11 \
                                       18 19 20 21 22 23 \
                                       30 31 32 33 34 35 \
                                       42 43 44 45 46 47 \
                                          51 52 53
  #define THUMB_KEYS           \
                      54 55 56   57 58 59

  #define LEFT_PINKY_KEY  KEY_LH_C5R3
  #define LEFT_RINGY_KEY  KEY_LH_C4R3
  #define LEFT_MIDDY_KEY  KEY_LH_C3R3
  #define LEFT_INDEX_KEY  KEY_LH_C2R3

  #define RIGHT_PINKY_KEY KEY_RH_C5R3
  #define RIGHT_RINGY_KEY KEY_RH_C4R3
  #define RIGHT_MIDDY_KEY KEY_RH_C3R3
  #define RIGHT_INDEX_KEY KEY_RH_C2R3

  //
  // Home row mods with bilateral combinations support
  //
  #ifndef PINKY_HOLDING_TYPE
  #define PINKY_HOLDING_TYPE HOMEY_HOLDING_TYPE
  #endif
  #ifndef PINKY_CHORD_HOLDING_TYPE
  #define PINKY_CHORD_HOLDING_TYPE CHORD_HOLDING_TYPE
  #endif
  #ifndef LEFT_PINKY_CHORD_HOLDING_TYPE
  #define LEFT_PINKY_CHORD_HOLDING_TYPE PINKY_CHORD_HOLDING_TYPE
  #endif
  #ifndef RIGHT_PINKY_CHORD_HOLDING_TYPE
  #define RIGHT_PINKY_CHORD_HOLDING_TYPE PINKY_CHORD_HOLDING_TYPE
  #endif
  #ifndef PINKY_HOLDING_TIME
  #define PINKY_HOLDING_TIME HOMEY_HOLDING_TIME
  #endif
  #ifndef PINKY_CHORD_HOLDING_TIME
  #define PINKY_CHORD_HOLDING_TIME CHORD_HOLDING_TIME
  #endif
  #ifndef LEFT_PINKY_CHORD_HOLDING_TIME
  #define LEFT_PINKY_CHORD_HOLDING_TIME PINKY_CHORD_HOLDING_TIME
  #endif
  #ifndef RIGHT_PINKY_CHORD_HOLDING_TIME
  #define RIGHT_PINKY_CHORD_HOLDING_TIME PINKY_CHORD_HOLDING_TIME
  #endif
  #ifndef PINKY_STREAK_DECAY
  #define PINKY_STREAK_DECAY HOMEY_STREAK_DECAY
  #endif
  #ifndef PINKY_CHORD_STREAK_DECAY
  #define PINKY_CHORD_STREAK_DECAY CHORD_STREAK_DECAY
  #endif
  #ifndef LEFT_PINKY_CHORD_STREAK_DECAY
  #define LEFT_PINKY_CHORD_STREAK_DECAY PINKY_CHORD_STREAK_DECAY
  #endif
  #ifndef RIGHT_PINKY_CHORD_STREAK_DECAY
  #define RIGHT_PINKY_CHORD_STREAK_DECAY PINKY_CHORD_STREAK_DECAY
  #endif
  #ifndef PINKY_REPEAT_DECAY
  #define PINKY_REPEAT_DECAY HOMEY_REPEAT_DECAY
  #endif
  #ifndef PINKY_CHORD_REPEAT_DECAY
  #define PINKY_CHORD_REPEAT_DECAY CHORD_REPEAT_DECAY
  #endif
  #ifndef LEFT_PINKY_CHORD_REPEAT_DECAY
  #define LEFT_PINKY_CHORD_REPEAT_DECAY PINKY_CHORD_REPEAT_DECAY
  #endif
  #ifndef RIGHT_PINKY_CHORD_REPEAT_DECAY
  #define RIGHT_PINKY_CHORD_REPEAT_DECAY PINKY_CHORD_REPEAT_DECAY
  #endif
  #ifndef RINGY_HOLDING_TYPE
  #define RINGY_HOLDING_TYPE HOMEY_HOLDING_TYPE
  #endif
  #ifndef RINGY_CHORD_HOLDING_TYPE
  #define RINGY_CHORD_HOLDING_TYPE CHORD_HOLDING_TYPE
  #endif
  #ifndef LEFT_RINGY_CHORD_HOLDING_TYPE
  #define LEFT_RINGY_CHORD_HOLDING_TYPE RINGY_CHORD_HOLDING_TYPE
  #endif
  #ifndef RIGHT_RINGY_CHORD_HOLDING_TYPE
  #define RIGHT_RINGY_CHORD_HOLDING_TYPE RINGY_CHORD_HOLDING_TYPE
  #endif
  #ifndef RINGY_HOLDING_TIME
  #define RINGY_HOLDING_TIME HOMEY_HOLDING_TIME
  #endif
  #ifndef RINGY_CHORD_HOLDING_TIME
  #define RINGY_CHORD_HOLDING_TIME CHORD_HOLDING_TIME
  #endif
  #ifndef LEFT_RINGY_CHORD_HOLDING_TIME
  #define LEFT_RINGY_CHORD_HOLDING_TIME RINGY_CHORD_HOLDING_TIME
  #endif
  #ifndef RIGHT_RINGY_CHORD_HOLDING_TIME
  #define RIGHT_RINGY_CHORD_HOLDING_TIME RINGY_CHORD_HOLDING_TIME
  #endif
  #ifndef RINGY_STREAK_DECAY
  #define RINGY_STREAK_DECAY HOMEY_STREAK_DECAY
  #endif
  #ifndef RINGY_CHORD_STREAK_DECAY
  #define RINGY_CHORD_STREAK_DECAY CHORD_STREAK_DECAY
  #endif
  #ifndef LEFT_RINGY_CHORD_STREAK_DECAY
  #define LEFT_RINGY_CHORD_STREAK_DECAY RINGY_CHORD_STREAK_DECAY
  #endif
  #ifndef RIGHT_RINGY_CHORD_STREAK_DECAY
  #define RIGHT_RINGY_CHORD_STREAK_DECAY RINGY_CHORD_STREAK_DECAY
  #endif
  #ifndef RINGY_REPEAT_DECAY
  #define RINGY_REPEAT_DECAY HOMEY_REPEAT_DECAY
  #endif
  #ifndef RINGY_CHORD_REPEAT_DECAY
  #define RINGY_CHORD_REPEAT_DECAY CHORD_REPEAT_DECAY
  #endif
  #ifndef LEFT_RINGY_CHORD_REPEAT_DECAY
  #define LEFT_RINGY_CHORD_REPEAT_DECAY RINGY_CHORD_REPEAT_DECAY
  #endif
  #ifndef RIGHT_RINGY_CHORD_REPEAT_DECAY
  #define RIGHT_RINGY_CHORD_REPEAT_DECAY RINGY_CHORD_REPEAT_DECAY
  #endif
  #ifndef MIDDY_HOLDING_TYPE
  #define MIDDY_HOLDING_TYPE HOMEY_HOLDING_TYPE
  #endif
  #ifndef MIDDY_CHORD_HOLDING_TYPE
  #define MIDDY_CHORD_HOLDING_TYPE CHORD_HOLDING_TYPE
  #endif
  #ifndef LEFT_MIDDY_CHORD_HOLDING_TYPE
  #define LEFT_MIDDY_CHORD_HOLDING_TYPE MIDDY_CHORD_HOLDING_TYPE
  #endif
  #ifndef RIGHT_MIDDY_CHORD_HOLDING_TYPE
  #define RIGHT_MIDDY_CHORD_HOLDING_TYPE MIDDY_CHORD_HOLDING_TYPE
  #endif
  #ifndef MIDDY_HOLDING_TIME
  #define MIDDY_HOLDING_TIME HOMEY_HOLDING_TIME
  #endif
  #ifndef MIDDY_CHORD_HOLDING_TIME
  #define MIDDY_CHORD_HOLDING_TIME CHORD_HOLDING_TIME
  #endif
  #ifndef LEFT_MIDDY_CHORD_HOLDING_TIME
  #define LEFT_MIDDY_CHORD_HOLDING_TIME MIDDY_CHORD_HOLDING_TIME
  #endif
  #ifndef RIGHT_MIDDY_CHORD_HOLDING_TIME
  #define RIGHT_MIDDY_CHORD_HOLDING_TIME MIDDY_CHORD_HOLDING_TIME
  #endif
  #ifndef MIDDY_STREAK_DECAY
  #define MIDDY_STREAK_DECAY HOMEY_STREAK_DECAY
  #endif
  #ifndef MIDDY_CHORD_STREAK_DECAY
  #define MIDDY_CHORD_STREAK_DECAY CHORD_STREAK_DECAY
  #endif
  #ifndef LEFT_MIDDY_CHORD_STREAK_DECAY
  #define LEFT_MIDDY_CHORD_STREAK_DECAY MIDDY_CHORD_STREAK_DECAY
  #endif
  #ifndef RIGHT_MIDDY_CHORD_STREAK_DECAY
  #define RIGHT_MIDDY_CHORD_STREAK_DECAY MIDDY_CHORD_STREAK_DECAY
  #endif
  #ifndef MIDDY_REPEAT_DECAY
  #define MIDDY_REPEAT_DECAY HOMEY_REPEAT_DECAY
  #endif
  #ifndef MIDDY_CHORD_REPEAT_DECAY
  #define MIDDY_CHORD_REPEAT_DECAY CHORD_REPEAT_DECAY
  #endif
  #ifndef LEFT_MIDDY_CHORD_REPEAT_DECAY
  #define LEFT_MIDDY_CHORD_REPEAT_DECAY MIDDY_CHORD_REPEAT_DECAY
  #endif
  #ifndef RIGHT_MIDDY_CHORD_REPEAT_DECAY
  #define RIGHT_MIDDY_CHORD_REPEAT_DECAY MIDDY_CHORD_REPEAT_DECAY
  #endif
  #ifndef INDEX_HOLDING_TYPE
  #define INDEX_HOLDING_TYPE HOMEY_HOLDING_TYPE
  #endif
  #ifndef INDEX_CHORD_HOLDING_TYPE
  #define INDEX_CHORD_HOLDING_TYPE CHORD_HOLDING_TYPE
  #endif
  #ifndef LEFT_INDEX_CHORD_HOLDING_TYPE
  #define LEFT_INDEX_CHORD_HOLDING_TYPE INDEX_CHORD_HOLDING_TYPE
  #endif
  #ifndef RIGHT_INDEX_CHORD_HOLDING_TYPE
  #define RIGHT_INDEX_CHORD_HOLDING_TYPE INDEX_CHORD_HOLDING_TYPE
  #endif
  #ifndef INDEX_HOLDING_TIME
  #define INDEX_HOLDING_TIME HOMEY_HOLDING_TIME
  #endif
  #ifndef INDEX_CHORD_HOLDING_TIME
  #define INDEX_CHORD_HOLDING_TIME CHORD_HOLDING_TIME
  #endif
  #ifndef LEFT_INDEX_CHORD_HOLDING_TIME
  #define LEFT_INDEX_CHORD_HOLDING_TIME INDEX_CHORD_HOLDING_TIME
  #endif
  #ifndef RIGHT_INDEX_CHORD_HOLDING_TIME
  #define RIGHT_INDEX_CHORD_HOLDING_TIME INDEX_CHORD_HOLDING_TIME
  #endif
  #ifndef INDEX_STREAK_DECAY
  #define INDEX_STREAK_DECAY HOMEY_STREAK_DECAY
  #endif
  #ifndef INDEX_CHORD_STREAK_DECAY
  #define INDEX_CHORD_STREAK_DECAY CHORD_STREAK_DECAY
  #endif
  #ifndef LEFT_INDEX_CHORD_STREAK_DECAY
  #define LEFT_INDEX_CHORD_STREAK_DECAY INDEX_CHORD_STREAK_DECAY
  #endif
  #ifndef RIGHT_INDEX_CHORD_STREAK_DECAY
  #define RIGHT_INDEX_CHORD_STREAK_DECAY INDEX_CHORD_STREAK_DECAY
  #endif
  #ifndef INDEX_REPEAT_DECAY
  #define INDEX_REPEAT_DECAY HOMEY_REPEAT_DECAY
  #endif
  #ifndef INDEX_CHORD_REPEAT_DECAY
  #define INDEX_CHORD_REPEAT_DECAY CHORD_REPEAT_DECAY
  #endif
  #ifndef LEFT_INDEX_CHORD_REPEAT_DECAY
  #define LEFT_INDEX_CHORD_REPEAT_DECAY INDEX_CHORD_REPEAT_DECAY
  #endif
  #ifndef RIGHT_INDEX_CHORD_REPEAT_DECAY
  #define RIGHT_INDEX_CHORD_REPEAT_DECAY INDEX_CHORD_REPEAT_DECAY
  #endif
  #ifndef LEFT_PINKY_HOLDING_TYPE
  #define LEFT_PINKY_HOLDING_TYPE PINKY_HOLDING_TYPE
  #endif
  #ifndef LEFT_PINKY_HOLDING_TIME
  #define LEFT_PINKY_HOLDING_TIME PINKY_HOLDING_TIME
  #endif
  #ifndef LEFT_PINKY_STREAK_DECAY
  #define LEFT_PINKY_STREAK_DECAY PINKY_STREAK_DECAY
  #endif
  #ifndef LEFT_PINKY_REPEAT_DECAY
  #define LEFT_PINKY_REPEAT_DECAY PINKY_REPEAT_DECAY
  #endif
  left_pinky: homey_left_pinky {
    compatible = "zmk,behavior-hold-tap";
    flavor = LEFT_PINKY_HOLDING_TYPE;
    hold-trigger-key-positions = <RIGHT_HAND_KEYS THUMB_KEYS>;
    hold-trigger-on-release; // wait for other home row mods
    tapping-term-ms = <LEFT_PINKY_HOLDING_TIME>;
    quick-tap-ms = <LEFT_PINKY_REPEAT_DECAY>;
    require-prior-idle-ms = <LEFT_PINKY_STREAK_DECAY>;
    #binding-cells = <2>;
    bindings = <&kp>, <&kp>;
  };
  left_pinky_bilateral: homey_left_pinky_bilateral {
    compatible = "zmk,behavior-hold-tap";
    flavor = LEFT_PINKY_HOLDING_TYPE;
    hold-trigger-key-positions = <RIGHT_HAND_KEYS THUMB_KEYS>;
    hold-trigger-on-release; // wait for other home row mods
    tapping-term-ms = <LEFT_PINKY_HOLDING_TIME>;
    quick-tap-ms = <LEFT_PINKY_REPEAT_DECAY>;
    require-prior-idle-ms = <LEFT_PINKY_STREAK_DECAY>;
    #binding-cells = <2>;
    bindings = <&left_pinky_hold>, <&kp>;
  };
  left_pinky_hold: homey_left_pinky_hold {
    compatible = "zmk,behavior-macro-one-param";
    wait-ms = <0>;
    tap-ms = <0>;
    #binding-cells = <1>;
    bindings
      = <&macro_param_1to1>
      , <&macro_press &kp MACRO_PLACEHOLDER>
      #ifdef LAYER_LeftPinky
      , <&macro_press &mo LAYER_LeftPinky>
      #endif
      , <&macro_pause_for_release>
      , <&macro_param_1to1>
      , <&macro_release &kp MACRO_PLACEHOLDER>
      #ifdef LAYER_LeftPinky
      , <&macro_release &mo LAYER_LeftPinky>
      #endif
      ;
  };
  left_pinky_tap: homey_left_pinky_tap {
    compatible = "zmk,behavior-macro-one-param";
    wait-ms = <0>;
    tap-ms = <0>;
    #binding-cells = <1>;
    bindings
      = <&macro_release
          &kp LSFT &kp RSFT
          &kp LALT &kp RALT
          &kp LCTL &kp RCTL
          &kp LGUI &kp RGUI>
      , <&macro_tap &kp LEFT_PINKY_KEY>
      , <&macro_param_1to1>
      , <&macro_tap &kp MACRO_PLACEHOLDER>
      ;
  };
  #define LeftPinky(key, layer_index) LeftPinky_unroll(layer_index) (key)
  #define LeftPinky_unroll(layer_index) LeftPinky_concat(LeftPinky_layer, layer_index)
  #define LeftPinky_concat(prefix, layer_index) prefix ## layer_index
  #ifdef ENFORCE_BILATERAL
  #define left_pinky_layer0_variant left_pinky_bilateral
  #else
  #define left_pinky_layer0_variant left_pinky
  #endif
  #define LeftPinky_layer0(key) left_pinky_layer0_variant LEFT_PINKY_MOD key
  #define LeftPinky_layer1(key) left_pinky LEFT_PINKY_MOD key
  #define LeftPinky_layer2(key) left_pinky LEFT_PINKY_MOD key
  #define LeftPinky_layer3(key) left_pinky LEFT_PINKY_MOD key
  #define LeftPinky_layer4(key) left_pinky LEFT_PINKY_MOD key
  #define LeftPinky_layer5(key) left_pinky LEFT_PINKY_MOD key
  #define LeftPinky_layer6(key) left_pinky LEFT_PINKY_MOD key
  #define LeftPinky_layer7(key) left_pinky LEFT_PINKY_MOD key
  #ifndef RIGHT_PINKY_HOLDING_TYPE
  #define RIGHT_PINKY_HOLDING_TYPE PINKY_HOLDING_TYPE
  #endif
  #ifndef RIGHT_PINKY_HOLDING_TIME
  #define RIGHT_PINKY_HOLDING_TIME PINKY_HOLDING_TIME
  #endif
  #ifndef RIGHT_PINKY_STREAK_DECAY
  #define RIGHT_PINKY_STREAK_DECAY PINKY_STREAK_DECAY
  #endif
  #ifndef RIGHT_PINKY_REPEAT_DECAY
  #define RIGHT_PINKY_REPEAT_DECAY PINKY_REPEAT_DECAY
  #endif
  right_pinky: homey_right_pinky {
    compatible = "zmk,behavior-hold-tap";
    flavor = RIGHT_PINKY_HOLDING_TYPE;
    hold-trigger-key-positions = <LEFT_HAND_KEYS THUMB_KEYS>;
    hold-trigger-on-release; // wait for other home row mods
    tapping-term-ms = <RIGHT_PINKY_HOLDING_TIME>;
    quick-tap-ms = <RIGHT_PINKY_REPEAT_DECAY>;
    require-prior-idle-ms = <RIGHT_PINKY_STREAK_DECAY>;
    #binding-cells = <2>;
    bindings = <&kp>, <&kp>;
  };
  right_pinky_bilateral: homey_right_pinky_bilateral {
    compatible = "zmk,behavior-hold-tap";
    flavor = RIGHT_PINKY_HOLDING_TYPE;
    hold-trigger-key-positions = <LEFT_HAND_KEYS THUMB_KEYS>;
    hold-trigger-on-release; // wait for other home row mods
    tapping-term-ms = <RIGHT_PINKY_HOLDING_TIME>;
    quick-tap-ms = <RIGHT_PINKY_REPEAT_DECAY>;
    require-prior-idle-ms = <RIGHT_PINKY_STREAK_DECAY>;
    #binding-cells = <2>;
    bindings = <&right_pinky_hold>, <&kp>;
  };
  right_pinky_hold: homey_right_pinky_hold {
    compatible = "zmk,behavior-macro-one-param";
    wait-ms = <0>;
    tap-ms = <0>;
    #binding-cells = <1>;
    bindings
      = <&macro_param_1to1>
      , <&macro_press &kp MACRO_PLACEHOLDER>
      #ifdef LAYER_RightPinky
      , <&macro_press &mo LAYER_RightPinky>
      #endif
      , <&macro_pause_for_release>
      , <&macro_param_1to1>
      , <&macro_release &kp MACRO_PLACEHOLDER>
      #ifdef LAYER_RightPinky
      , <&macro_release &mo LAYER_RightPinky>
      #endif
      ;
  };
  right_pinky_tap: homey_right_pinky_tap {
    compatible = "zmk,behavior-macro-one-param";
    wait-ms = <0>;
    tap-ms = <0>;
    #binding-cells = <1>;
    bindings
      = <&macro_release
          &kp LSFT &kp RSFT
          &kp LALT &kp RALT
          &kp LCTL &kp RCTL
          &kp LGUI &kp RGUI>
      , <&macro_tap &kp RIGHT_PINKY_KEY>
      , <&macro_param_1to1>
      , <&macro_tap &kp MACRO_PLACEHOLDER>
      ;
  };
  #define RightPinky(key, layer_index) RightPinky_unroll(layer_index) (key)
  #define RightPinky_unroll(layer_index) RightPinky_concat(RightPinky_layer, layer_index)
  #define RightPinky_concat(prefix, layer_index) prefix ## layer_index
  #ifdef ENFORCE_BILATERAL
  #define right_pinky_layer0_variant right_pinky_bilateral
  #else
  #define right_pinky_layer0_variant right_pinky
  #endif
  #define RightPinky_layer0(key) right_pinky_layer0_variant RIGHT_PINKY_MOD key
  #define RightPinky_layer1(key) right_pinky RIGHT_PINKY_MOD key
  #define RightPinky_layer2(key) right_pinky RIGHT_PINKY_MOD key
  #define RightPinky_layer3(key) right_pinky RIGHT_PINKY_MOD key
  #define RightPinky_layer4(key) right_pinky RIGHT_PINKY_MOD key
  #define RightPinky_layer5(key) right_pinky RIGHT_PINKY_MOD key
  #define RightPinky_layer6(key) right_pinky RIGHT_PINKY_MOD key
  #define RightPinky_layer7(key) right_pinky RIGHT_PINKY_MOD key
  #ifndef LEFT_RINGY_HOLDING_TYPE
  #define LEFT_RINGY_HOLDING_TYPE RINGY_HOLDING_TYPE
  #endif
  #ifndef LEFT_RINGY_HOLDING_TIME
  #define LEFT_RINGY_HOLDING_TIME RINGY_HOLDING_TIME
  #endif
  #ifndef LEFT_RINGY_STREAK_DECAY
  #define LEFT_RINGY_STREAK_DECAY RINGY_STREAK_DECAY
  #endif
  #ifndef LEFT_RINGY_REPEAT_DECAY
  #define LEFT_RINGY_REPEAT_DECAY RINGY_REPEAT_DECAY
  #endif
  left_ringy: homey_left_ringy {
    compatible = "zmk,behavior-hold-tap";
    flavor = LEFT_RINGY_HOLDING_TYPE;
    hold-trigger-key-positions = <RIGHT_HAND_KEYS THUMB_KEYS>;
    hold-trigger-on-release; // wait for other home row mods
    tapping-term-ms = <LEFT_RINGY_HOLDING_TIME>;
    quick-tap-ms = <LEFT_RINGY_REPEAT_DECAY>;
    require-prior-idle-ms = <LEFT_RINGY_STREAK_DECAY>;
    #binding-cells = <2>;
    bindings = <&kp>, <&kp>;
  };
  left_ringy_bilateral: homey_left_ringy_bilateral {
    compatible = "zmk,behavior-hold-tap";
    flavor = LEFT_RINGY_HOLDING_TYPE;
    hold-trigger-key-positions = <RIGHT_HAND_KEYS THUMB_KEYS>;
    hold-trigger-on-release; // wait for other home row mods
    tapping-term-ms = <LEFT_RINGY_HOLDING_TIME>;
    quick-tap-ms = <LEFT_RINGY_REPEAT_DECAY>;
    require-prior-idle-ms = <LEFT_RINGY_STREAK_DECAY>;
    #binding-cells = <2>;
    bindings = <&left_ringy_hold>, <&kp>;
  };
  left_ringy_hold: homey_left_ringy_hold {
    compatible = "zmk,behavior-macro-one-param";
    wait-ms = <0>;
    tap-ms = <0>;
    #binding-cells = <1>;
    bindings
      = <&macro_param_1to1>
      , <&macro_press &kp MACRO_PLACEHOLDER>
      #ifdef LAYER_LeftRingy
      , <&macro_press &mo LAYER_LeftRingy>
      #endif
      , <&macro_pause_for_release>
      , <&macro_param_1to1>
      , <&macro_release &kp MACRO_PLACEHOLDER>
      #ifdef LAYER_LeftRingy
      , <&macro_release &mo LAYER_LeftRingy>
      #endif
      ;
  };
  left_ringy_tap: homey_left_ringy_tap {
    compatible = "zmk,behavior-macro-one-param";
    wait-ms = <0>;
    tap-ms = <0>;
    #binding-cells = <1>;
    bindings
      = <&macro_release
          &kp LSFT &kp RSFT
          &kp LALT &kp RALT
          &kp LCTL &kp RCTL
          &kp LGUI &kp RGUI>
      , <&macro_tap &kp LEFT_RINGY_KEY>
      , <&macro_param_1to1>
      , <&macro_tap &kp MACRO_PLACEHOLDER>
      ;
  };
  #define LeftRingy(key, layer_index) LeftRingy_unroll(layer_index) (key)
  #define LeftRingy_unroll(layer_index) LeftRingy_concat(LeftRingy_layer, layer_index)
  #define LeftRingy_concat(prefix, layer_index) prefix ## layer_index
  #ifdef ENFORCE_BILATERAL
  #define left_ringy_layer0_variant left_ringy_bilateral
  #else
  #define left_ringy_layer0_variant left_ringy
  #endif
  #define LeftRingy_layer0(key) left_ringy_layer0_variant LEFT_RINGY_MOD key
  #define LeftRingy_layer1(key) left_ringy LEFT_RINGY_MOD key
  #define LeftRingy_layer2(key) left_ringy LEFT_RINGY_MOD key
  #define LeftRingy_layer3(key) left_ringy LEFT_RINGY_MOD key
  #define LeftRingy_layer4(key) left_ringy LEFT_RINGY_MOD key
  #define LeftRingy_layer5(key) left_ringy LEFT_RINGY_MOD key
  #define LeftRingy_layer6(key) left_ringy LEFT_RINGY_MOD key
  #define LeftRingy_layer7(key) left_ringy LEFT_RINGY_MOD key
  #ifndef RIGHT_RINGY_HOLDING_TYPE
  #define RIGHT_RINGY_HOLDING_TYPE RINGY_HOLDING_TYPE
  #endif
  #ifndef RIGHT_RINGY_HOLDING_TIME
  #define RIGHT_RINGY_HOLDING_TIME RINGY_HOLDING_TIME
  #endif
  #ifndef RIGHT_RINGY_STREAK_DECAY
  #define RIGHT_RINGY_STREAK_DECAY RINGY_STREAK_DECAY
  #endif
  #ifndef RIGHT_RINGY_REPEAT_DECAY
  #define RIGHT_RINGY_REPEAT_DECAY RINGY_REPEAT_DECAY
  #endif
  right_ringy: homey_right_ringy {
    compatible = "zmk,behavior-hold-tap";
    flavor = RIGHT_RINGY_HOLDING_TYPE;
    hold-trigger-key-positions = <LEFT_HAND_KEYS THUMB_KEYS>;
    hold-trigger-on-release; // wait for other home row mods
    tapping-term-ms = <RIGHT_RINGY_HOLDING_TIME>;
    quick-tap-ms = <RIGHT_RINGY_REPEAT_DECAY>;
    require-prior-idle-ms = <RIGHT_RINGY_STREAK_DECAY>;
    #binding-cells = <2>;
    bindings = <&kp>, <&kp>;
  };
  right_ringy_bilateral: homey_right_ringy_bilateral {
    compatible = "zmk,behavior-hold-tap";
    flavor = RIGHT_RINGY_HOLDING_TYPE;
    hold-trigger-key-positions = <LEFT_HAND_KEYS THUMB_KEYS>;
    hold-trigger-on-release; // wait for other home row mods
    tapping-term-ms = <RIGHT_RINGY_HOLDING_TIME>;
    quick-tap-ms = <RIGHT_RINGY_REPEAT_DECAY>;
    require-prior-idle-ms = <RIGHT_RINGY_STREAK_DECAY>;
    #binding-cells = <2>;
    bindings = <&right_ringy_hold>, <&kp>;
  };
  right_ringy_hold: homey_right_ringy_hold {
    compatible = "zmk,behavior-macro-one-param";
    wait-ms = <0>;
    tap-ms = <0>;
    #binding-cells = <1>;
    bindings
      = <&macro_param_1to1>
      , <&macro_press &kp MACRO_PLACEHOLDER>
      #ifdef LAYER_RightRingy
      , <&macro_press &mo LAYER_RightRingy>
      #endif
      , <&macro_pause_for_release>
      , <&macro_param_1to1>
      , <&macro_release &kp MACRO_PLACEHOLDER>
      #ifdef LAYER_RightRingy
      , <&macro_release &mo LAYER_RightRingy>
      #endif
      ;
  };
  right_ringy_tap: homey_right_ringy_tap {
    compatible = "zmk,behavior-macro-one-param";
    wait-ms = <0>;
    tap-ms = <0>;
    #binding-cells = <1>;
    bindings
      = <&macro_release
          &kp LSFT &kp RSFT
          &kp LALT &kp RALT
          &kp LCTL &kp RCTL
          &kp LGUI &kp RGUI>
      , <&macro_tap &kp RIGHT_RINGY_KEY>
      , <&macro_param_1to1>
      , <&macro_tap &kp MACRO_PLACEHOLDER>
      ;
  };
  #define RightRingy(key, layer_index) RightRingy_unroll(layer_index) (key)
  #define RightRingy_unroll(layer_index) RightRingy_concat(RightRingy_layer, layer_index)
  #define RightRingy_concat(prefix, layer_index) prefix ## layer_index
  #ifdef ENFORCE_BILATERAL
  #define right_ringy_layer0_variant right_ringy_bilateral
  #else
  #define right_ringy_layer0_variant right_ringy
  #endif
  #define RightRingy_layer0(key) right_ringy_layer0_variant RIGHT_RINGY_MOD key
  #define RightRingy_layer1(key) right_ringy RIGHT_RINGY_MOD key
  #define RightRingy_layer2(key) right_ringy RIGHT_RINGY_MOD key
  #define RightRingy_layer3(key) right_ringy RIGHT_RINGY_MOD key
  #define RightRingy_layer4(key) right_ringy RIGHT_RINGY_MOD key
  #define RightRingy_layer5(key) right_ringy RIGHT_RINGY_MOD key
  #define RightRingy_layer6(key) right_ringy RIGHT_RINGY_MOD key
  #define RightRingy_layer7(key) right_ringy RIGHT_RINGY_MOD key
  #ifndef LEFT_MIDDY_HOLDING_TYPE
  #define LEFT_MIDDY_HOLDING_TYPE MIDDY_HOLDING_TYPE
  #endif
  #ifndef LEFT_MIDDY_HOLDING_TIME
  #define LEFT_MIDDY_HOLDING_TIME MIDDY_HOLDING_TIME
  #endif
  #ifndef LEFT_MIDDY_STREAK_DECAY
  #define LEFT_MIDDY_STREAK_DECAY MIDDY_STREAK_DECAY
  #endif
  #ifndef LEFT_MIDDY_REPEAT_DECAY
  #define LEFT_MIDDY_REPEAT_DECAY MIDDY_REPEAT_DECAY
  #endif
  left_middy: homey_left_middy {
    compatible = "zmk,behavior-hold-tap";
    flavor = LEFT_MIDDY_HOLDING_TYPE;
    hold-trigger-key-positions = <RIGHT_HAND_KEYS THUMB_KEYS>;
    hold-trigger-on-release; // wait for other home row mods
    tapping-term-ms = <LEFT_MIDDY_HOLDING_TIME>;
    quick-tap-ms = <LEFT_MIDDY_REPEAT_DECAY>;
    require-prior-idle-ms = <LEFT_MIDDY_STREAK_DECAY>;
    #binding-cells = <2>;
    bindings = <&kp>, <&kp>;
  };
  left_middy_bilateral: homey_left_middy_bilateral {
    compatible = "zmk,behavior-hold-tap";
    flavor = LEFT_MIDDY_HOLDING_TYPE;
    hold-trigger-key-positions = <RIGHT_HAND_KEYS THUMB_KEYS>;
    hold-trigger-on-release; // wait for other home row mods
    tapping-term-ms = <LEFT_MIDDY_HOLDING_TIME>;
    quick-tap-ms = <LEFT_MIDDY_REPEAT_DECAY>;
    require-prior-idle-ms = <LEFT_MIDDY_STREAK_DECAY>;
    #binding-cells = <2>;
    bindings = <&left_middy_hold>, <&kp>;
  };
  left_middy_hold: homey_left_middy_hold {
    compatible = "zmk,behavior-macro-one-param";
    wait-ms = <0>;
    tap-ms = <0>;
    #binding-cells = <1>;
    bindings
      = <&macro_param_1to1>
      , <&macro_press &kp MACRO_PLACEHOLDER>
      #ifdef LAYER_LeftMiddy
      , <&macro_press &mo LAYER_LeftMiddy>
      #endif
      , <&macro_pause_for_release>
      , <&macro_param_1to1>
      , <&macro_release &kp MACRO_PLACEHOLDER>
      #ifdef LAYER_LeftMiddy
      , <&macro_release &mo LAYER_LeftMiddy>
      #endif
      ;
  };
  left_middy_tap: homey_left_middy_tap {
    compatible = "zmk,behavior-macro-one-param";
    wait-ms = <0>;
    tap-ms = <0>;
    #binding-cells = <1>;
    bindings
      = <&macro_release
          &kp LSFT &kp RSFT
          &kp LALT &kp RALT
          &kp LCTL &kp RCTL
          &kp LGUI &kp RGUI>
      , <&macro_tap &kp LEFT_MIDDY_KEY>
      , <&macro_param_1to1>
      , <&macro_tap &kp MACRO_PLACEHOLDER>
      ;
  };
  #define LeftMiddy(key, layer_index) LeftMiddy_unroll(layer_index) (key)
  #define LeftMiddy_unroll(layer_index) LeftMiddy_concat(LeftMiddy_layer, layer_index)
  #define LeftMiddy_concat(prefix, layer_index) prefix ## layer_index
  #ifdef ENFORCE_BILATERAL
  #define left_middy_layer0_variant left_middy_bilateral
  #else
  #define left_middy_layer0_variant left_middy
  #endif
  #define LeftMiddy_layer0(key) left_middy_layer0_variant LEFT_MIDDY_MOD key
  #define LeftMiddy_layer1(key) left_middy LEFT_MIDDY_MOD key
  #define LeftMiddy_layer2(key) left_middy LEFT_MIDDY_MOD key
  #define LeftMiddy_layer3(key) left_middy LEFT_MIDDY_MOD key
  #define LeftMiddy_layer4(key) left_middy LEFT_MIDDY_MOD key
  #define LeftMiddy_layer5(key) left_middy LEFT_MIDDY_MOD key
  #define LeftMiddy_layer6(key) left_middy LEFT_MIDDY_MOD key
  #define LeftMiddy_layer7(key) left_middy LEFT_MIDDY_MOD key
  #ifndef RIGHT_MIDDY_HOLDING_TYPE
  #define RIGHT_MIDDY_HOLDING_TYPE MIDDY_HOLDING_TYPE
  #endif
  #ifndef RIGHT_MIDDY_HOLDING_TIME
  #define RIGHT_MIDDY_HOLDING_TIME MIDDY_HOLDING_TIME
  #endif
  #ifndef RIGHT_MIDDY_STREAK_DECAY
  #define RIGHT_MIDDY_STREAK_DECAY MIDDY_STREAK_DECAY
  #endif
  #ifndef RIGHT_MIDDY_REPEAT_DECAY
  #define RIGHT_MIDDY_REPEAT_DECAY MIDDY_REPEAT_DECAY
  #endif
  right_middy: homey_right_middy {
    compatible = "zmk,behavior-hold-tap";
    flavor = RIGHT_MIDDY_HOLDING_TYPE;
    hold-trigger-key-positions = <LEFT_HAND_KEYS THUMB_KEYS>;
    hold-trigger-on-release; // wait for other home row mods
    tapping-term-ms = <RIGHT_MIDDY_HOLDING_TIME>;
    quick-tap-ms = <RIGHT_MIDDY_REPEAT_DECAY>;
    require-prior-idle-ms = <RIGHT_MIDDY_STREAK_DECAY>;
    #binding-cells = <2>;
    bindings = <&kp>, <&kp>;
  };
  right_middy_bilateral: homey_right_middy_bilateral {
    compatible = "zmk,behavior-hold-tap";
    flavor = RIGHT_MIDDY_HOLDING_TYPE;
    hold-trigger-key-positions = <LEFT_HAND_KEYS THUMB_KEYS>;
    hold-trigger-on-release; // wait for other home row mods
    tapping-term-ms = <RIGHT_MIDDY_HOLDING_TIME>;
    quick-tap-ms = <RIGHT_MIDDY_REPEAT_DECAY>;
    require-prior-idle-ms = <RIGHT_MIDDY_STREAK_DECAY>;
    #binding-cells = <2>;
    bindings = <&right_middy_hold>, <&kp>;
  };
  right_middy_hold: homey_right_middy_hold {
    compatible = "zmk,behavior-macro-one-param";
    wait-ms = <0>;
    tap-ms = <0>;
    #binding-cells = <1>;
    bindings
      = <&macro_param_1to1>
      , <&macro_press &kp MACRO_PLACEHOLDER>
      #ifdef LAYER_RightMiddy
      , <&macro_press &mo LAYER_RightMiddy>
      #endif
      , <&macro_pause_for_release>
      , <&macro_param_1to1>
      , <&macro_release &kp MACRO_PLACEHOLDER>
      #ifdef LAYER_RightMiddy
      , <&macro_release &mo LAYER_RightMiddy>
      #endif
      ;
  };
  right_middy_tap: homey_right_middy_tap {
    compatible = "zmk,behavior-macro-one-param";
    wait-ms = <0>;
    tap-ms = <0>;
    #binding-cells = <1>;
    bindings
      = <&macro_release
          &kp LSFT &kp RSFT
          &kp LALT &kp RALT
          &kp LCTL &kp RCTL
          &kp LGUI &kp RGUI>
      , <&macro_tap &kp RIGHT_MIDDY_KEY>
      , <&macro_param_1to1>
      , <&macro_tap &kp MACRO_PLACEHOLDER>
      ;
  };
  #define RightMiddy(key, layer_index) RightMiddy_unroll(layer_index) (key)
  #define RightMiddy_unroll(layer_index) RightMiddy_concat(RightMiddy_layer, layer_index)
  #define RightMiddy_concat(prefix, layer_index) prefix ## layer_index
  #ifdef ENFORCE_BILATERAL
  #define right_middy_layer0_variant right_middy_bilateral
  #else
  #define right_middy_layer0_variant right_middy
  #endif
  #define RightMiddy_layer0(key) right_middy_layer0_variant RIGHT_MIDDY_MOD key
  #define RightMiddy_layer1(key) right_middy RIGHT_MIDDY_MOD key
  #define RightMiddy_layer2(key) right_middy RIGHT_MIDDY_MOD key
  #define RightMiddy_layer3(key) right_middy RIGHT_MIDDY_MOD key
  #define RightMiddy_layer4(key) right_middy RIGHT_MIDDY_MOD key
  #define RightMiddy_layer5(key) right_middy RIGHT_MIDDY_MOD key
  #define RightMiddy_layer6(key) right_middy RIGHT_MIDDY_MOD key
  #define RightMiddy_layer7(key) right_middy RIGHT_MIDDY_MOD key
  #ifndef LEFT_INDEX_HOLDING_TYPE
  #define LEFT_INDEX_HOLDING_TYPE INDEX_HOLDING_TYPE
  #endif
  #ifndef LEFT_INDEX_HOLDING_TIME
  #define LEFT_INDEX_HOLDING_TIME INDEX_HOLDING_TIME
  #endif
  #ifndef LEFT_INDEX_STREAK_DECAY
  #define LEFT_INDEX_STREAK_DECAY INDEX_STREAK_DECAY
  #endif
  #ifndef LEFT_INDEX_REPEAT_DECAY
  #define LEFT_INDEX_REPEAT_DECAY INDEX_REPEAT_DECAY
  #endif
  left_index: homey_left_index {
    compatible = "zmk,behavior-hold-tap";
    flavor = LEFT_INDEX_HOLDING_TYPE;
    hold-trigger-key-positions = <RIGHT_HAND_KEYS THUMB_KEYS>;
    hold-trigger-on-release; // wait for other home row mods
    tapping-term-ms = <LEFT_INDEX_HOLDING_TIME>;
    quick-tap-ms = <LEFT_INDEX_REPEAT_DECAY>;
    require-prior-idle-ms = <LEFT_INDEX_STREAK_DECAY>;
    #binding-cells = <2>;
    bindings = <&kp>, <&kp>;
  };
  left_index_bilateral: homey_left_index_bilateral {
    compatible = "zmk,behavior-hold-tap";
    flavor = LEFT_INDEX_HOLDING_TYPE;
    hold-trigger-key-positions = <RIGHT_HAND_KEYS THUMB_KEYS>;
    hold-trigger-on-release; // wait for other home row mods
    tapping-term-ms = <LEFT_INDEX_HOLDING_TIME>;
    quick-tap-ms = <LEFT_INDEX_REPEAT_DECAY>;
    require-prior-idle-ms = <LEFT_INDEX_STREAK_DECAY>;
    #binding-cells = <2>;
    bindings = <&left_index_hold>, <&kp>;
  };
  left_index_hold: homey_left_index_hold {
    compatible = "zmk,behavior-macro-one-param";
    wait-ms = <0>;
    tap-ms = <0>;
    #binding-cells = <1>;
    bindings
      = <&macro_param_1to1>
      , <&macro_press &kp MACRO_PLACEHOLDER>
      #ifdef LAYER_LeftIndex
      , <&macro_press &mo LAYER_LeftIndex>
      #endif
      , <&macro_pause_for_release>
      , <&macro_param_1to1>
      , <&macro_release &kp MACRO_PLACEHOLDER>
      #ifdef LAYER_LeftIndex
      , <&macro_release &mo LAYER_LeftIndex>
      #endif
      ;
  };
  left_index_tap: homey_left_index_tap {
    compatible = "zmk,behavior-macro-one-param";
    wait-ms = <0>;
    tap-ms = <0>;
    #binding-cells = <1>;
    bindings
      = <&macro_release
          &kp LSFT &kp RSFT
          &kp LALT &kp RALT
          &kp LCTL &kp RCTL
          &kp LGUI &kp RGUI>
      , <&macro_tap &kp LEFT_INDEX_KEY>
      , <&macro_param_1to1>
      , <&macro_tap &kp MACRO_PLACEHOLDER>
      ;
  };
  #define LeftIndex(key, layer_index) LeftIndex_unroll(layer_index) (key)
  #define LeftIndex_unroll(layer_index) LeftIndex_concat(LeftIndex_layer, layer_index)
  #define LeftIndex_concat(prefix, layer_index) prefix ## layer_index
  #ifdef ENFORCE_BILATERAL
  #define left_index_layer0_variant left_index_bilateral
  #else
  #define left_index_layer0_variant left_index
  #endif
  #define LeftIndex_layer0(key) left_index_layer0_variant LEFT_INDEX_MOD key
  #define LeftIndex_layer1(key) left_index LEFT_INDEX_MOD key
  #define LeftIndex_layer2(key) left_index LEFT_INDEX_MOD key
  #define LeftIndex_layer3(key) left_index LEFT_INDEX_MOD key
  #define LeftIndex_layer4(key) left_index LEFT_INDEX_MOD key
  #define LeftIndex_layer5(key) left_index LEFT_INDEX_MOD key
  #define LeftIndex_layer6(key) left_index LEFT_INDEX_MOD key
  #define LeftIndex_layer7(key) left_index LEFT_INDEX_MOD key
  #ifndef RIGHT_INDEX_HOLDING_TYPE
  #define RIGHT_INDEX_HOLDING_TYPE INDEX_HOLDING_TYPE
  #endif
  #ifndef RIGHT_INDEX_HOLDING_TIME
  #define RIGHT_INDEX_HOLDING_TIME INDEX_HOLDING_TIME
  #endif
  #ifndef RIGHT_INDEX_STREAK_DECAY
  #define RIGHT_INDEX_STREAK_DECAY INDEX_STREAK_DECAY
  #endif
  #ifndef RIGHT_INDEX_REPEAT_DECAY
  #define RIGHT_INDEX_REPEAT_DECAY INDEX_REPEAT_DECAY
  #endif
  right_index: homey_right_index {
    compatible = "zmk,behavior-hold-tap";
    flavor = RIGHT_INDEX_HOLDING_TYPE;
    hold-trigger-key-positions = <LEFT_HAND_KEYS THUMB_KEYS>;
    hold-trigger-on-release; // wait for other home row mods
    tapping-term-ms = <RIGHT_INDEX_HOLDING_TIME>;
    quick-tap-ms = <RIGHT_INDEX_REPEAT_DECAY>;
    require-prior-idle-ms = <RIGHT_INDEX_STREAK_DECAY>;
    #binding-cells = <2>;
    bindings = <&kp>, <&kp>;
  };
  right_index_bilateral: homey_right_index_bilateral {
    compatible = "zmk,behavior-hold-tap";
    flavor = RIGHT_INDEX_HOLDING_TYPE;
    hold-trigger-key-positions = <LEFT_HAND_KEYS THUMB_KEYS>;
    hold-trigger-on-release; // wait for other home row mods
    tapping-term-ms = <RIGHT_INDEX_HOLDING_TIME>;
    quick-tap-ms = <RIGHT_INDEX_REPEAT_DECAY>;
    require-prior-idle-ms = <RIGHT_INDEX_STREAK_DECAY>;
    #binding-cells = <2>;
    bindings = <&right_index_hold>, <&kp>;
  };
  right_index_hold: homey_right_index_hold {
    compatible = "zmk,behavior-macro-one-param";
    wait-ms = <0>;
    tap-ms = <0>;
    #binding-cells = <1>;
    bindings
      = <&macro_param_1to1>
      , <&macro_press &kp MACRO_PLACEHOLDER>
      #ifdef LAYER_RightIndex
      , <&macro_press &mo LAYER_RightIndex>
      #endif
      , <&macro_pause_for_release>
      , <&macro_param_1to1>
      , <&macro_release &kp MACRO_PLACEHOLDER>
      #ifdef LAYER_RightIndex
      , <&macro_release &mo LAYER_RightIndex>
      #endif
      ;
  };
  right_index_tap: homey_right_index_tap {
    compatible = "zmk,behavior-macro-one-param";
    wait-ms = <0>;
    tap-ms = <0>;
    #binding-cells = <1>;
    bindings
      = <&macro_release
          &kp LSFT &kp RSFT
          &kp LALT &kp RALT
          &kp LCTL &kp RCTL
          &kp LGUI &kp RGUI>
      , <&macro_tap &kp RIGHT_INDEX_KEY>
      , <&macro_param_1to1>
      , <&macro_tap &kp MACRO_PLACEHOLDER>
      ;
  };
  #define RightIndex(key, layer_index) RightIndex_unroll(layer_index) (key)
  #define RightIndex_unroll(layer_index) RightIndex_concat(RightIndex_layer, layer_index)
  #define RightIndex_concat(prefix, layer_index) prefix ## layer_index
  #ifdef ENFORCE_BILATERAL
  #define right_index_layer0_variant right_index_bilateral
  #else
  #define right_index_layer0_variant right_index
  #endif
  #define RightIndex_layer0(key) right_index_layer0_variant RIGHT_INDEX_MOD key
  #define RightIndex_layer1(key) right_index RIGHT_INDEX_MOD key
  #define RightIndex_layer2(key) right_index RIGHT_INDEX_MOD key
  #define RightIndex_layer3(key) right_index RIGHT_INDEX_MOD key
  #define RightIndex_layer4(key) right_index RIGHT_INDEX_MOD key
  #define RightIndex_layer5(key) right_index RIGHT_INDEX_MOD key
  #define RightIndex_layer6(key) right_index RIGHT_INDEX_MOD key
  #define RightIndex_layer7(key) right_index RIGHT_INDEX_MOD key
  #ifndef LEFT_RINGY_PINKY_HOLDING_TYPE
  #define LEFT_RINGY_PINKY_HOLDING_TYPE LEFT_RINGY_CHORD_HOLDING_TYPE
  #endif
  #ifndef LEFT_RINGY_PINKY_HOLDING_TIME
  #define LEFT_RINGY_PINKY_HOLDING_TIME LEFT_RINGY_CHORD_HOLDING_TIME
  #endif
  #ifndef LEFT_RINGY_PINKY_STREAK_DECAY
  #define LEFT_RINGY_PINKY_STREAK_DECAY LEFT_RINGY_CHORD_STREAK_DECAY
  #endif
  #ifndef LEFT_RINGY_PINKY_REPEAT_DECAY
  #define LEFT_RINGY_PINKY_REPEAT_DECAY LEFT_RINGY_CHORD_REPEAT_DECAY
  #endif
  left_ringy_pinky: homey_left_ringy_pinky {
    compatible = "zmk,behavior-hold-tap";
    flavor = LEFT_RINGY_HOLDING_TYPE;
    hold-trigger-key-positions = <RIGHT_HAND_KEYS THUMB_KEYS>;
    hold-trigger-on-release; // wait for other home row mods
    tapping-term-ms = <LEFT_RINGY_HOLDING_TIME>;
    quick-tap-ms = <LEFT_RINGY_REPEAT_DECAY>;
    require-prior-idle-ms = <LEFT_RINGY_STREAK_DECAY>;
    #binding-cells = <2>;
    bindings = <&kp>, <&kp>;
  };
  left_ringy_pinky_bilateral: homey_left_ringy_pinky_bilateral {
    compatible = "zmk,behavior-hold-tap";
    flavor = LEFT_RINGY_HOLDING_TYPE;
    hold-trigger-key-positions = <RIGHT_HAND_KEYS THUMB_KEYS>;
    hold-trigger-on-release; // wait for other home row mods
    tapping-term-ms = <LEFT_RINGY_HOLDING_TIME>;
    quick-tap-ms = <LEFT_RINGY_REPEAT_DECAY>;
    require-prior-idle-ms = <LEFT_RINGY_STREAK_DECAY>;
    #binding-cells = <2>;
    bindings = <&kp>, <&left_ringy_tap>;
  };
  #define LeftRingyPinky left_ringy_pinky_bilateral LEFT_PINKY_MOD LEFT_PINKY_KEY
  #ifndef LEFT_MIDDY_PINKY_HOLDING_TYPE
  #define LEFT_MIDDY_PINKY_HOLDING_TYPE LEFT_MIDDY_CHORD_HOLDING_TYPE
  #endif
  #ifndef LEFT_MIDDY_PINKY_HOLDING_TIME
  #define LEFT_MIDDY_PINKY_HOLDING_TIME LEFT_MIDDY_CHORD_HOLDING_TIME
  #endif
  #ifndef LEFT_MIDDY_PINKY_STREAK_DECAY
  #define LEFT_MIDDY_PINKY_STREAK_DECAY LEFT_MIDDY_CHORD_STREAK_DECAY
  #endif
  #ifndef LEFT_MIDDY_PINKY_REPEAT_DECAY
  #define LEFT_MIDDY_PINKY_REPEAT_DECAY LEFT_MIDDY_CHORD_REPEAT_DECAY
  #endif
  left_middy_pinky: homey_left_middy_pinky {
    compatible = "zmk,behavior-hold-tap";
    flavor = LEFT_MIDDY_HOLDING_TYPE;
    hold-trigger-key-positions = <RIGHT_HAND_KEYS THUMB_KEYS>;
    hold-trigger-on-release; // wait for other home row mods
    tapping-term-ms = <LEFT_MIDDY_HOLDING_TIME>;
    quick-tap-ms = <LEFT_MIDDY_REPEAT_DECAY>;
    require-prior-idle-ms = <LEFT_MIDDY_STREAK_DECAY>;
    #binding-cells = <2>;
    bindings = <&kp>, <&kp>;
  };
  left_middy_pinky_bilateral: homey_left_middy_pinky_bilateral {
    compatible = "zmk,behavior-hold-tap";
    flavor = LEFT_MIDDY_HOLDING_TYPE;
    hold-trigger-key-positions = <RIGHT_HAND_KEYS THUMB_KEYS>;
    hold-trigger-on-release; // wait for other home row mods
    tapping-term-ms = <LEFT_MIDDY_HOLDING_TIME>;
    quick-tap-ms = <LEFT_MIDDY_REPEAT_DECAY>;
    require-prior-idle-ms = <LEFT_MIDDY_STREAK_DECAY>;
    #binding-cells = <2>;
    bindings = <&kp>, <&left_middy_tap>;
  };
  #define LeftMiddyPinky left_middy_pinky_bilateral LEFT_PINKY_MOD LEFT_PINKY_KEY
  #ifndef LEFT_INDEX_PINKY_HOLDING_TYPE
  #define LEFT_INDEX_PINKY_HOLDING_TYPE LEFT_INDEX_CHORD_HOLDING_TYPE
  #endif
  #ifndef LEFT_INDEX_PINKY_HOLDING_TIME
  #define LEFT_INDEX_PINKY_HOLDING_TIME LEFT_INDEX_CHORD_HOLDING_TIME
  #endif
  #ifndef LEFT_INDEX_PINKY_STREAK_DECAY
  #define LEFT_INDEX_PINKY_STREAK_DECAY LEFT_INDEX_CHORD_STREAK_DECAY
  #endif
  #ifndef LEFT_INDEX_PINKY_REPEAT_DECAY
  #define LEFT_INDEX_PINKY_REPEAT_DECAY LEFT_INDEX_CHORD_REPEAT_DECAY
  #endif
  left_index_pinky: homey_left_index_pinky {
    compatible = "zmk,behavior-hold-tap";
    flavor = LEFT_INDEX_HOLDING_TYPE;
    hold-trigger-key-positions = <RIGHT_HAND_KEYS THUMB_KEYS>;
    hold-trigger-on-release; // wait for other home row mods
    tapping-term-ms = <LEFT_INDEX_HOLDING_TIME>;
    quick-tap-ms = <LEFT_INDEX_REPEAT_DECAY>;
    require-prior-idle-ms = <LEFT_INDEX_STREAK_DECAY>;
    #binding-cells = <2>;
    bindings = <&kp>, <&kp>;
  };
  left_index_pinky_bilateral: homey_left_index_pinky_bilateral {
    compatible = "zmk,behavior-hold-tap";
    flavor = LEFT_INDEX_HOLDING_TYPE;
    hold-trigger-key-positions = <RIGHT_HAND_KEYS THUMB_KEYS>;
    hold-trigger-on-release; // wait for other home row mods
    tapping-term-ms = <LEFT_INDEX_HOLDING_TIME>;
    quick-tap-ms = <LEFT_INDEX_REPEAT_DECAY>;
    require-prior-idle-ms = <LEFT_INDEX_STREAK_DECAY>;
    #binding-cells = <2>;
    bindings = <&kp>, <&left_index_tap>;
  };
  #define LeftIndexPinky left_index_pinky_bilateral LEFT_PINKY_MOD LEFT_PINKY_KEY
  #ifndef RIGHT_RINGY_PINKY_HOLDING_TYPE
  #define RIGHT_RINGY_PINKY_HOLDING_TYPE RIGHT_RINGY_CHORD_HOLDING_TYPE
  #endif
  #ifndef RIGHT_RINGY_PINKY_HOLDING_TIME
  #define RIGHT_RINGY_PINKY_HOLDING_TIME RIGHT_RINGY_CHORD_HOLDING_TIME
  #endif
  #ifndef RIGHT_RINGY_PINKY_STREAK_DECAY
  #define RIGHT_RINGY_PINKY_STREAK_DECAY RIGHT_RINGY_CHORD_STREAK_DECAY
  #endif
  #ifndef RIGHT_RINGY_PINKY_REPEAT_DECAY
  #define RIGHT_RINGY_PINKY_REPEAT_DECAY RIGHT_RINGY_CHORD_REPEAT_DECAY
  #endif
  right_ringy_pinky: homey_right_ringy_pinky {
    compatible = "zmk,behavior-hold-tap";
    flavor = RIGHT_RINGY_HOLDING_TYPE;
    hold-trigger-key-positions = <LEFT_HAND_KEYS THUMB_KEYS>;
    hold-trigger-on-release; // wait for other home row mods
    tapping-term-ms = <RIGHT_RINGY_HOLDING_TIME>;
    quick-tap-ms = <RIGHT_RINGY_REPEAT_DECAY>;
    require-prior-idle-ms = <RIGHT_RINGY_STREAK_DECAY>;
    #binding-cells = <2>;
    bindings = <&kp>, <&kp>;
  };
  right_ringy_pinky_bilateral: homey_right_ringy_pinky_bilateral {
    compatible = "zmk,behavior-hold-tap";
    flavor = RIGHT_RINGY_HOLDING_TYPE;
    hold-trigger-key-positions = <LEFT_HAND_KEYS THUMB_KEYS>;
    hold-trigger-on-release; // wait for other home row mods
    tapping-term-ms = <RIGHT_RINGY_HOLDING_TIME>;
    quick-tap-ms = <RIGHT_RINGY_REPEAT_DECAY>;
    require-prior-idle-ms = <RIGHT_RINGY_STREAK_DECAY>;
    #binding-cells = <2>;
    bindings = <&kp>, <&right_ringy_tap>;
  };
  #define RightRingyPinky right_ringy_pinky_bilateral RIGHT_PINKY_MOD RIGHT_PINKY_KEY
  #ifndef RIGHT_MIDDY_PINKY_HOLDING_TYPE
  #define RIGHT_MIDDY_PINKY_HOLDING_TYPE RIGHT_MIDDY_CHORD_HOLDING_TYPE
  #endif
  #ifndef RIGHT_MIDDY_PINKY_HOLDING_TIME
  #define RIGHT_MIDDY_PINKY_HOLDING_TIME RIGHT_MIDDY_CHORD_HOLDING_TIME
  #endif
  #ifndef RIGHT_MIDDY_PINKY_STREAK_DECAY
  #define RIGHT_MIDDY_PINKY_STREAK_DECAY RIGHT_MIDDY_CHORD_STREAK_DECAY
  #endif
  #ifndef RIGHT_MIDDY_PINKY_REPEAT_DECAY
  #define RIGHT_MIDDY_PINKY_REPEAT_DECAY RIGHT_MIDDY_CHORD_REPEAT_DECAY
  #endif
  right_middy_pinky: homey_right_middy_pinky {
    compatible = "zmk,behavior-hold-tap";
    flavor = RIGHT_MIDDY_HOLDING_TYPE;
    hold-trigger-key-positions = <LEFT_HAND_KEYS THUMB_KEYS>;
    hold-trigger-on-release; // wait for other home row mods
    tapping-term-ms = <RIGHT_MIDDY_HOLDING_TIME>;
    quick-tap-ms = <RIGHT_MIDDY_REPEAT_DECAY>;
    require-prior-idle-ms = <RIGHT_MIDDY_STREAK_DECAY>;
    #binding-cells = <2>;
    bindings = <&kp>, <&kp>;
  };
  right_middy_pinky_bilateral: homey_right_middy_pinky_bilateral {
    compatible = "zmk,behavior-hold-tap";
    flavor = RIGHT_MIDDY_HOLDING_TYPE;
    hold-trigger-key-positions = <LEFT_HAND_KEYS THUMB_KEYS>;
    hold-trigger-on-release; // wait for other home row mods
    tapping-term-ms = <RIGHT_MIDDY_HOLDING_TIME>;
    quick-tap-ms = <RIGHT_MIDDY_REPEAT_DECAY>;
    require-prior-idle-ms = <RIGHT_MIDDY_STREAK_DECAY>;
    #binding-cells = <2>;
    bindings = <&kp>, <&right_middy_tap>;
  };
  #define RightMiddyPinky right_middy_pinky_bilateral RIGHT_PINKY_MOD RIGHT_PINKY_KEY
  #ifndef RIGHT_INDEX_PINKY_HOLDING_TYPE
  #define RIGHT_INDEX_PINKY_HOLDING_TYPE RIGHT_INDEX_CHORD_HOLDING_TYPE
  #endif
  #ifndef RIGHT_INDEX_PINKY_HOLDING_TIME
  #define RIGHT_INDEX_PINKY_HOLDING_TIME RIGHT_INDEX_CHORD_HOLDING_TIME
  #endif
  #ifndef RIGHT_INDEX_PINKY_STREAK_DECAY
  #define RIGHT_INDEX_PINKY_STREAK_DECAY RIGHT_INDEX_CHORD_STREAK_DECAY
  #endif
  #ifndef RIGHT_INDEX_PINKY_REPEAT_DECAY
  #define RIGHT_INDEX_PINKY_REPEAT_DECAY RIGHT_INDEX_CHORD_REPEAT_DECAY
  #endif
  right_index_pinky: homey_right_index_pinky {
    compatible = "zmk,behavior-hold-tap";
    flavor = RIGHT_INDEX_HOLDING_TYPE;
    hold-trigger-key-positions = <LEFT_HAND_KEYS THUMB_KEYS>;
    hold-trigger-on-release; // wait for other home row mods
    tapping-term-ms = <RIGHT_INDEX_HOLDING_TIME>;
    quick-tap-ms = <RIGHT_INDEX_REPEAT_DECAY>;
    require-prior-idle-ms = <RIGHT_INDEX_STREAK_DECAY>;
    #binding-cells = <2>;
    bindings = <&kp>, <&kp>;
  };
  right_index_pinky_bilateral: homey_right_index_pinky_bilateral {
    compatible = "zmk,behavior-hold-tap";
    flavor = RIGHT_INDEX_HOLDING_TYPE;
    hold-trigger-key-positions = <LEFT_HAND_KEYS THUMB_KEYS>;
    hold-trigger-on-release; // wait for other home row mods
    tapping-term-ms = <RIGHT_INDEX_HOLDING_TIME>;
    quick-tap-ms = <RIGHT_INDEX_REPEAT_DECAY>;
    require-prior-idle-ms = <RIGHT_INDEX_STREAK_DECAY>;
    #binding-cells = <2>;
    bindings = <&kp>, <&right_index_tap>;
  };
  #define RightIndexPinky right_index_pinky_bilateral RIGHT_PINKY_MOD RIGHT_PINKY_KEY
  #ifndef LEFT_PINKY_RINGY_HOLDING_TYPE
  #define LEFT_PINKY_RINGY_HOLDING_TYPE LEFT_PINKY_CHORD_HOLDING_TYPE
  #endif
  #ifndef LEFT_PINKY_RINGY_HOLDING_TIME
  #define LEFT_PINKY_RINGY_HOLDING_TIME LEFT_PINKY_CHORD_HOLDING_TIME
  #endif
  #ifndef LEFT_PINKY_RINGY_STREAK_DECAY
  #define LEFT_PINKY_RINGY_STREAK_DECAY LEFT_PINKY_CHORD_STREAK_DECAY
  #endif
  #ifndef LEFT_PINKY_RINGY_REPEAT_DECAY
  #define LEFT_PINKY_RINGY_REPEAT_DECAY LEFT_PINKY_CHORD_REPEAT_DECAY
  #endif
  left_pinky_ringy: homey_left_pinky_ringy {
    compatible = "zmk,behavior-hold-tap";
    flavor = LEFT_PINKY_HOLDING_TYPE;
    hold-trigger-key-positions = <RIGHT_HAND_KEYS THUMB_KEYS>;
    hold-trigger-on-release; // wait for other home row mods
    tapping-term-ms = <LEFT_PINKY_HOLDING_TIME>;
    quick-tap-ms = <LEFT_PINKY_REPEAT_DECAY>;
    require-prior-idle-ms = <LEFT_PINKY_STREAK_DECAY>;
    #binding-cells = <2>;
    bindings = <&kp>, <&kp>;
  };
  left_pinky_ringy_bilateral: homey_left_pinky_ringy_bilateral {
    compatible = "zmk,behavior-hold-tap";
    flavor = LEFT_PINKY_HOLDING_TYPE;
    hold-trigger-key-positions = <RIGHT_HAND_KEYS THUMB_KEYS>;
    hold-trigger-on-release; // wait for other home row mods
    tapping-term-ms = <LEFT_PINKY_HOLDING_TIME>;
    quick-tap-ms = <LEFT_PINKY_REPEAT_DECAY>;
    require-prior-idle-ms = <LEFT_PINKY_STREAK_DECAY>;
    #binding-cells = <2>;
    bindings = <&kp>, <&left_pinky_tap>;
  };
  #define LeftPinkyRingy left_pinky_ringy_bilateral LEFT_RINGY_MOD LEFT_RINGY_KEY
  #ifndef LEFT_MIDDY_RINGY_HOLDING_TYPE
  #define LEFT_MIDDY_RINGY_HOLDING_TYPE LEFT_MIDDY_CHORD_HOLDING_TYPE
  #endif
  #ifndef LEFT_MIDDY_RINGY_HOLDING_TIME
  #define LEFT_MIDDY_RINGY_HOLDING_TIME LEFT_MIDDY_CHORD_HOLDING_TIME
  #endif
  #ifndef LEFT_MIDDY_RINGY_STREAK_DECAY
  #define LEFT_MIDDY_RINGY_STREAK_DECAY LEFT_MIDDY_CHORD_STREAK_DECAY
  #endif
  #ifndef LEFT_MIDDY_RINGY_REPEAT_DECAY
  #define LEFT_MIDDY_RINGY_REPEAT_DECAY LEFT_MIDDY_CHORD_REPEAT_DECAY
  #endif
  left_middy_ringy: homey_left_middy_ringy {
    compatible = "zmk,behavior-hold-tap";
    flavor = LEFT_MIDDY_HOLDING_TYPE;
    hold-trigger-key-positions = <RIGHT_HAND_KEYS THUMB_KEYS>;
    hold-trigger-on-release; // wait for other home row mods
    tapping-term-ms = <LEFT_MIDDY_HOLDING_TIME>;
    quick-tap-ms = <LEFT_MIDDY_REPEAT_DECAY>;
    require-prior-idle-ms = <LEFT_MIDDY_STREAK_DECAY>;
    #binding-cells = <2>;
    bindings = <&kp>, <&kp>;
  };
  left_middy_ringy_bilateral: homey_left_middy_ringy_bilateral {
    compatible = "zmk,behavior-hold-tap";
    flavor = LEFT_MIDDY_HOLDING_TYPE;
    hold-trigger-key-positions = <RIGHT_HAND_KEYS THUMB_KEYS>;
    hold-trigger-on-release; // wait for other home row mods
    tapping-term-ms = <LEFT_MIDDY_HOLDING_TIME>;
    quick-tap-ms = <LEFT_MIDDY_REPEAT_DECAY>;
    require-prior-idle-ms = <LEFT_MIDDY_STREAK_DECAY>;
    #binding-cells = <2>;
    bindings = <&kp>, <&left_middy_tap>;
  };
  #define LeftMiddyRingy left_middy_ringy_bilateral LEFT_RINGY_MOD LEFT_RINGY_KEY
  #ifndef LEFT_INDEX_RINGY_HOLDING_TYPE
  #define LEFT_INDEX_RINGY_HOLDING_TYPE LEFT_INDEX_CHORD_HOLDING_TYPE
  #endif
  #ifndef LEFT_INDEX_RINGY_HOLDING_TIME
  #define LEFT_INDEX_RINGY_HOLDING_TIME LEFT_INDEX_CHORD_HOLDING_TIME
  #endif
  #ifndef LEFT_INDEX_RINGY_STREAK_DECAY
  #define LEFT_INDEX_RINGY_STREAK_DECAY LEFT_INDEX_CHORD_STREAK_DECAY
  #endif
  #ifndef LEFT_INDEX_RINGY_REPEAT_DECAY
  #define LEFT_INDEX_RINGY_REPEAT_DECAY LEFT_INDEX_CHORD_REPEAT_DECAY
  #endif
  left_index_ringy: homey_left_index_ringy {
    compatible = "zmk,behavior-hold-tap";
    flavor = LEFT_INDEX_HOLDING_TYPE;
    hold-trigger-key-positions = <RIGHT_HAND_KEYS THUMB_KEYS>;
    hold-trigger-on-release; // wait for other home row mods
    tapping-term-ms = <LEFT_INDEX_HOLDING_TIME>;
    quick-tap-ms = <LEFT_INDEX_REPEAT_DECAY>;
    require-prior-idle-ms = <LEFT_INDEX_STREAK_DECAY>;
    #binding-cells = <2>;
    bindings = <&kp>, <&kp>;
  };
  left_index_ringy_bilateral: homey_left_index_ringy_bilateral {
    compatible = "zmk,behavior-hold-tap";
    flavor = LEFT_INDEX_HOLDING_TYPE;
    hold-trigger-key-positions = <RIGHT_HAND_KEYS THUMB_KEYS>;
    hold-trigger-on-release; // wait for other home row mods
    tapping-term-ms = <LEFT_INDEX_HOLDING_TIME>;
    quick-tap-ms = <LEFT_INDEX_REPEAT_DECAY>;
    require-prior-idle-ms = <LEFT_INDEX_STREAK_DECAY>;
    #binding-cells = <2>;
    bindings = <&kp>, <&left_index_tap>;
  };
  #define LeftIndexRingy left_index_ringy_bilateral LEFT_RINGY_MOD LEFT_RINGY_KEY
  #ifndef RIGHT_PINKY_RINGY_HOLDING_TYPE
  #define RIGHT_PINKY_RINGY_HOLDING_TYPE RIGHT_PINKY_CHORD_HOLDING_TYPE
  #endif
  #ifndef RIGHT_PINKY_RINGY_HOLDING_TIME
  #define RIGHT_PINKY_RINGY_HOLDING_TIME RIGHT_PINKY_CHORD_HOLDING_TIME
  #endif
  #ifndef RIGHT_PINKY_RINGY_STREAK_DECAY
  #define RIGHT_PINKY_RINGY_STREAK_DECAY RIGHT_PINKY_CHORD_STREAK_DECAY
  #endif
  #ifndef RIGHT_PINKY_RINGY_REPEAT_DECAY
  #define RIGHT_PINKY_RINGY_REPEAT_DECAY RIGHT_PINKY_CHORD_REPEAT_DECAY
  #endif
  right_pinky_ringy: homey_right_pinky_ringy {
    compatible = "zmk,behavior-hold-tap";
    flavor = RIGHT_PINKY_HOLDING_TYPE;
    hold-trigger-key-positions = <LEFT_HAND_KEYS THUMB_KEYS>;
    hold-trigger-on-release; // wait for other home row mods
    tapping-term-ms = <RIGHT_PINKY_HOLDING_TIME>;
    quick-tap-ms = <RIGHT_PINKY_REPEAT_DECAY>;
    require-prior-idle-ms = <RIGHT_PINKY_STREAK_DECAY>;
    #binding-cells = <2>;
    bindings = <&kp>, <&kp>;
  };
  right_pinky_ringy_bilateral: homey_right_pinky_ringy_bilateral {
    compatible = "zmk,behavior-hold-tap";
    flavor = RIGHT_PINKY_HOLDING_TYPE;
    hold-trigger-key-positions = <LEFT_HAND_KEYS THUMB_KEYS>;
    hold-trigger-on-release; // wait for other home row mods
    tapping-term-ms = <RIGHT_PINKY_HOLDING_TIME>;
    quick-tap-ms = <RIGHT_PINKY_REPEAT_DECAY>;
    require-prior-idle-ms = <RIGHT_PINKY_STREAK_DECAY>;
    #binding-cells = <2>;
    bindings = <&kp>, <&right_pinky_tap>;
  };
  #define RightPinkyRingy right_pinky_ringy_bilateral RIGHT_RINGY_MOD RIGHT_RINGY_KEY
  #ifndef RIGHT_MIDDY_RINGY_HOLDING_TYPE
  #define RIGHT_MIDDY_RINGY_HOLDING_TYPE RIGHT_MIDDY_CHORD_HOLDING_TYPE
  #endif
  #ifndef RIGHT_MIDDY_RINGY_HOLDING_TIME
  #define RIGHT_MIDDY_RINGY_HOLDING_TIME RIGHT_MIDDY_CHORD_HOLDING_TIME
  #endif
  #ifndef RIGHT_MIDDY_RINGY_STREAK_DECAY
  #define RIGHT_MIDDY_RINGY_STREAK_DECAY RIGHT_MIDDY_CHORD_STREAK_DECAY
  #endif
  #ifndef RIGHT_MIDDY_RINGY_REPEAT_DECAY
  #define RIGHT_MIDDY_RINGY_REPEAT_DECAY RIGHT_MIDDY_CHORD_REPEAT_DECAY
  #endif
  right_middy_ringy: homey_right_middy_ringy {
    compatible = "zmk,behavior-hold-tap";
    flavor = RIGHT_MIDDY_HOLDING_TYPE;
    hold-trigger-key-positions = <LEFT_HAND_KEYS THUMB_KEYS>;
    hold-trigger-on-release; // wait for other home row mods
    tapping-term-ms = <RIGHT_MIDDY_HOLDING_TIME>;
    quick-tap-ms = <RIGHT_MIDDY_REPEAT_DECAY>;
    require-prior-idle-ms = <RIGHT_MIDDY_STREAK_DECAY>;
    #binding-cells = <2>;
    bindings = <&kp>, <&kp>;
  };
  right_middy_ringy_bilateral: homey_right_middy_ringy_bilateral {
    compatible = "zmk,behavior-hold-tap";
    flavor = RIGHT_MIDDY_HOLDING_TYPE;
    hold-trigger-key-positions = <LEFT_HAND_KEYS THUMB_KEYS>;
    hold-trigger-on-release; // wait for other home row mods
    tapping-term-ms = <RIGHT_MIDDY_HOLDING_TIME>;
    quick-tap-ms = <RIGHT_MIDDY_REPEAT_DECAY>;
    require-prior-idle-ms = <RIGHT_MIDDY_STREAK_DECAY>;
    #binding-cells = <2>;
    bindings = <&kp>, <&right_middy_tap>;
  };
  #define RightMiddyRingy right_middy_ringy_bilateral RIGHT_RINGY_MOD RIGHT_RINGY_KEY
  #ifndef RIGHT_INDEX_RINGY_HOLDING_TYPE
  #define RIGHT_INDEX_RINGY_HOLDING_TYPE RIGHT_INDEX_CHORD_HOLDING_TYPE
  #endif
  #ifndef RIGHT_INDEX_RINGY_HOLDING_TIME
  #define RIGHT_INDEX_RINGY_HOLDING_TIME RIGHT_INDEX_CHORD_HOLDING_TIME
  #endif
  #ifndef RIGHT_INDEX_RINGY_STREAK_DECAY
  #define RIGHT_INDEX_RINGY_STREAK_DECAY RIGHT_INDEX_CHORD_STREAK_DECAY
  #endif
  #ifndef RIGHT_INDEX_RINGY_REPEAT_DECAY
  #define RIGHT_INDEX_RINGY_REPEAT_DECAY RIGHT_INDEX_CHORD_REPEAT_DECAY
  #endif
  right_index_ringy: homey_right_index_ringy {
    compatible = "zmk,behavior-hold-tap";
    flavor = RIGHT_INDEX_HOLDING_TYPE;
    hold-trigger-key-positions = <LEFT_HAND_KEYS THUMB_KEYS>;
    hold-trigger-on-release; // wait for other home row mods
    tapping-term-ms = <RIGHT_INDEX_HOLDING_TIME>;
    quick-tap-ms = <RIGHT_INDEX_REPEAT_DECAY>;
    require-prior-idle-ms = <RIGHT_INDEX_STREAK_DECAY>;
    #binding-cells = <2>;
    bindings = <&kp>, <&kp>;
  };
  right_index_ringy_bilateral: homey_right_index_ringy_bilateral {
    compatible = "zmk,behavior-hold-tap";
    flavor = RIGHT_INDEX_HOLDING_TYPE;
    hold-trigger-key-positions = <LEFT_HAND_KEYS THUMB_KEYS>;
    hold-trigger-on-release; // wait for other home row mods
    tapping-term-ms = <RIGHT_INDEX_HOLDING_TIME>;
    quick-tap-ms = <RIGHT_INDEX_REPEAT_DECAY>;
    require-prior-idle-ms = <RIGHT_INDEX_STREAK_DECAY>;
    #binding-cells = <2>;
    bindings = <&kp>, <&right_index_tap>;
  };
  #define RightIndexRingy right_index_ringy_bilateral RIGHT_RINGY_MOD RIGHT_RINGY_KEY
  #ifndef LEFT_PINKY_MIDDY_HOLDING_TYPE
  #define LEFT_PINKY_MIDDY_HOLDING_TYPE LEFT_PINKY_CHORD_HOLDING_TYPE
  #endif
  #ifndef LEFT_PINKY_MIDDY_HOLDING_TIME
  #define LEFT_PINKY_MIDDY_HOLDING_TIME LEFT_PINKY_CHORD_HOLDING_TIME
  #endif
  #ifndef LEFT_PINKY_MIDDY_STREAK_DECAY
  #define LEFT_PINKY_MIDDY_STREAK_DECAY LEFT_PINKY_CHORD_STREAK_DECAY
  #endif
  #ifndef LEFT_PINKY_MIDDY_REPEAT_DECAY
  #define LEFT_PINKY_MIDDY_REPEAT_DECAY LEFT_PINKY_CHORD_REPEAT_DECAY
  #endif
  left_pinky_middy: homey_left_pinky_middy {
    compatible = "zmk,behavior-hold-tap";
    flavor = LEFT_PINKY_HOLDING_TYPE;
    hold-trigger-key-positions = <RIGHT_HAND_KEYS THUMB_KEYS>;
    hold-trigger-on-release; // wait for other home row mods
    tapping-term-ms = <LEFT_PINKY_HOLDING_TIME>;
    quick-tap-ms = <LEFT_PINKY_REPEAT_DECAY>;
    require-prior-idle-ms = <LEFT_PINKY_STREAK_DECAY>;
    #binding-cells = <2>;
    bindings = <&kp>, <&kp>;
  };
  left_pinky_middy_bilateral: homey_left_pinky_middy_bilateral {
    compatible = "zmk,behavior-hold-tap";
    flavor = LEFT_PINKY_HOLDING_TYPE;
    hold-trigger-key-positions = <RIGHT_HAND_KEYS THUMB_KEYS>;
    hold-trigger-on-release; // wait for other home row mods
    tapping-term-ms = <LEFT_PINKY_HOLDING_TIME>;
    quick-tap-ms = <LEFT_PINKY_REPEAT_DECAY>;
    require-prior-idle-ms = <LEFT_PINKY_STREAK_DECAY>;
    #binding-cells = <2>;
    bindings = <&kp>, <&left_pinky_tap>;
  };
  #define LeftPinkyMiddy left_pinky_middy_bilateral LEFT_MIDDY_MOD LEFT_MIDDY_KEY
  #ifndef LEFT_RINGY_MIDDY_HOLDING_TYPE
  #define LEFT_RINGY_MIDDY_HOLDING_TYPE LEFT_RINGY_CHORD_HOLDING_TYPE
  #endif
  #ifndef LEFT_RINGY_MIDDY_HOLDING_TIME
  #define LEFT_RINGY_MIDDY_HOLDING_TIME LEFT_RINGY_CHORD_HOLDING_TIME
  #endif
  #ifndef LEFT_RINGY_MIDDY_STREAK_DECAY
  #define LEFT_RINGY_MIDDY_STREAK_DECAY LEFT_RINGY_CHORD_STREAK_DECAY
  #endif
  #ifndef LEFT_RINGY_MIDDY_REPEAT_DECAY
  #define LEFT_RINGY_MIDDY_REPEAT_DECAY LEFT_RINGY_CHORD_REPEAT_DECAY
  #endif
  left_ringy_middy: homey_left_ringy_middy {
    compatible = "zmk,behavior-hold-tap";
    flavor = LEFT_RINGY_HOLDING_TYPE;
    hold-trigger-key-positions = <RIGHT_HAND_KEYS THUMB_KEYS>;
    hold-trigger-on-release; // wait for other home row mods
    tapping-term-ms = <LEFT_RINGY_HOLDING_TIME>;
    quick-tap-ms = <LEFT_RINGY_REPEAT_DECAY>;
    require-prior-idle-ms = <LEFT_RINGY_STREAK_DECAY>;
    #binding-cells = <2>;
    bindings = <&kp>, <&kp>;
  };
  left_ringy_middy_bilateral: homey_left_ringy_middy_bilateral {
    compatible = "zmk,behavior-hold-tap";
    flavor = LEFT_RINGY_HOLDING_TYPE;
    hold-trigger-key-positions = <RIGHT_HAND_KEYS THUMB_KEYS>;
    hold-trigger-on-release; // wait for other home row mods
    tapping-term-ms = <LEFT_RINGY_HOLDING_TIME>;
    quick-tap-ms = <LEFT_RINGY_REPEAT_DECAY>;
    require-prior-idle-ms = <LEFT_RINGY_STREAK_DECAY>;
    #binding-cells = <2>;
    bindings = <&kp>, <&left_ringy_tap>;
  };
  #define LeftRingyMiddy left_ringy_middy_bilateral LEFT_MIDDY_MOD LEFT_MIDDY_KEY
  #ifndef LEFT_INDEX_MIDDY_HOLDING_TYPE
  #define LEFT_INDEX_MIDDY_HOLDING_TYPE LEFT_INDEX_CHORD_HOLDING_TYPE
  #endif
  #ifndef LEFT_INDEX_MIDDY_HOLDING_TIME
  #define LEFT_INDEX_MIDDY_HOLDING_TIME LEFT_INDEX_CHORD_HOLDING_TIME
  #endif
  #ifndef LEFT_INDEX_MIDDY_STREAK_DECAY
  #define LEFT_INDEX_MIDDY_STREAK_DECAY LEFT_INDEX_CHORD_STREAK_DECAY
  #endif
  #ifndef LEFT_INDEX_MIDDY_REPEAT_DECAY
  #define LEFT_INDEX_MIDDY_REPEAT_DECAY LEFT_INDEX_CHORD_REPEAT_DECAY
  #endif
  left_index_middy: homey_left_index_middy {
    compatible = "zmk,behavior-hold-tap";
    flavor = LEFT_INDEX_HOLDING_TYPE;
    hold-trigger-key-positions = <RIGHT_HAND_KEYS THUMB_KEYS>;
    hold-trigger-on-release; // wait for other home row mods
    tapping-term-ms = <LEFT_INDEX_HOLDING_TIME>;
    quick-tap-ms = <LEFT_INDEX_REPEAT_DECAY>;
    require-prior-idle-ms = <LEFT_INDEX_STREAK_DECAY>;
    #binding-cells = <2>;
    bindings = <&kp>, <&kp>;
  };
  left_index_middy_bilateral: homey_left_index_middy_bilateral {
    compatible = "zmk,behavior-hold-tap";
    flavor = LEFT_INDEX_HOLDING_TYPE;
    hold-trigger-key-positions = <RIGHT_HAND_KEYS THUMB_KEYS>;
    hold-trigger-on-release; // wait for other home row mods
    tapping-term-ms = <LEFT_INDEX_HOLDING_TIME>;
    quick-tap-ms = <LEFT_INDEX_REPEAT_DECAY>;
    require-prior-idle-ms = <LEFT_INDEX_STREAK_DECAY>;
    #binding-cells = <2>;
    bindings = <&kp>, <&left_index_tap>;
  };
  #define LeftIndexMiddy left_index_middy_bilateral LEFT_MIDDY_MOD LEFT_MIDDY_KEY
  #ifndef RIGHT_PINKY_MIDDY_HOLDING_TYPE
  #define RIGHT_PINKY_MIDDY_HOLDING_TYPE RIGHT_PINKY_CHORD_HOLDING_TYPE
  #endif
  #ifndef RIGHT_PINKY_MIDDY_HOLDING_TIME
  #define RIGHT_PINKY_MIDDY_HOLDING_TIME RIGHT_PINKY_CHORD_HOLDING_TIME
  #endif
  #ifndef RIGHT_PINKY_MIDDY_STREAK_DECAY
  #define RIGHT_PINKY_MIDDY_STREAK_DECAY RIGHT_PINKY_CHORD_STREAK_DECAY
  #endif
  #ifndef RIGHT_PINKY_MIDDY_REPEAT_DECAY
  #define RIGHT_PINKY_MIDDY_REPEAT_DECAY RIGHT_PINKY_CHORD_REPEAT_DECAY
  #endif
  right_pinky_middy: homey_right_pinky_middy {
    compatible = "zmk,behavior-hold-tap";
    flavor = RIGHT_PINKY_HOLDING_TYPE;
    hold-trigger-key-positions = <LEFT_HAND_KEYS THUMB_KEYS>;
    hold-trigger-on-release; // wait for other home row mods
    tapping-term-ms = <RIGHT_PINKY_HOLDING_TIME>;
    quick-tap-ms = <RIGHT_PINKY_REPEAT_DECAY>;
    require-prior-idle-ms = <RIGHT_PINKY_STREAK_DECAY>;
    #binding-cells = <2>;
    bindings = <&kp>, <&kp>;
  };
  right_pinky_middy_bilateral: homey_right_pinky_middy_bilateral {
    compatible = "zmk,behavior-hold-tap";
    flavor = RIGHT_PINKY_HOLDING_TYPE;
    hold-trigger-key-positions = <LEFT_HAND_KEYS THUMB_KEYS>;
    hold-trigger-on-release; // wait for other home row mods
    tapping-term-ms = <RIGHT_PINKY_HOLDING_TIME>;
    quick-tap-ms = <RIGHT_PINKY_REPEAT_DECAY>;
    require-prior-idle-ms = <RIGHT_PINKY_STREAK_DECAY>;
    #binding-cells = <2>;
    bindings = <&kp>, <&right_pinky_tap>;
  };
  #define RightPinkyMiddy right_pinky_middy_bilateral RIGHT_MIDDY_MOD RIGHT_MIDDY_KEY
  #ifndef RIGHT_RINGY_MIDDY_HOLDING_TYPE
  #define RIGHT_RINGY_MIDDY_HOLDING_TYPE RIGHT_RINGY_CHORD_HOLDING_TYPE
  #endif
  #ifndef RIGHT_RINGY_MIDDY_HOLDING_TIME
  #define RIGHT_RINGY_MIDDY_HOLDING_TIME RIGHT_RINGY_CHORD_HOLDING_TIME
  #endif
  #ifndef RIGHT_RINGY_MIDDY_STREAK_DECAY
  #define RIGHT_RINGY_MIDDY_STREAK_DECAY RIGHT_RINGY_CHORD_STREAK_DECAY
  #endif
  #ifndef RIGHT_RINGY_MIDDY_REPEAT_DECAY
  #define RIGHT_RINGY_MIDDY_REPEAT_DECAY RIGHT_RINGY_CHORD_REPEAT_DECAY
  #endif
  right_ringy_middy: homey_right_ringy_middy {
    compatible = "zmk,behavior-hold-tap";
    flavor = RIGHT_RINGY_HOLDING_TYPE;
    hold-trigger-key-positions = <LEFT_HAND_KEYS THUMB_KEYS>;
    hold-trigger-on-release; // wait for other home row mods
    tapping-term-ms = <RIGHT_RINGY_HOLDING_TIME>;
    quick-tap-ms = <RIGHT_RINGY_REPEAT_DECAY>;
    require-prior-idle-ms = <RIGHT_RINGY_STREAK_DECAY>;
    #binding-cells = <2>;
    bindings = <&kp>, <&kp>;
  };
  right_ringy_middy_bilateral: homey_right_ringy_middy_bilateral {
    compatible = "zmk,behavior-hold-tap";
    flavor = RIGHT_RINGY_HOLDING_TYPE;
    hold-trigger-key-positions = <LEFT_HAND_KEYS THUMB_KEYS>;
    hold-trigger-on-release; // wait for other home row mods
    tapping-term-ms = <RIGHT_RINGY_HOLDING_TIME>;
    quick-tap-ms = <RIGHT_RINGY_REPEAT_DECAY>;
    require-prior-idle-ms = <RIGHT_RINGY_STREAK_DECAY>;
    #binding-cells = <2>;
    bindings = <&kp>, <&right_ringy_tap>;
  };
  #define RightRingyMiddy right_ringy_middy_bilateral RIGHT_MIDDY_MOD RIGHT_MIDDY_KEY
  #ifndef RIGHT_INDEX_MIDDY_HOLDING_TYPE
  #define RIGHT_INDEX_MIDDY_HOLDING_TYPE RIGHT_INDEX_CHORD_HOLDING_TYPE
  #endif
  #ifndef RIGHT_INDEX_MIDDY_HOLDING_TIME
  #define RIGHT_INDEX_MIDDY_HOLDING_TIME RIGHT_INDEX_CHORD_HOLDING_TIME
  #endif
  #ifndef RIGHT_INDEX_MIDDY_STREAK_DECAY
  #define RIGHT_INDEX_MIDDY_STREAK_DECAY RIGHT_INDEX_CHORD_STREAK_DECAY
  #endif
  #ifndef RIGHT_INDEX_MIDDY_REPEAT_DECAY
  #define RIGHT_INDEX_MIDDY_REPEAT_DECAY RIGHT_INDEX_CHORD_REPEAT_DECAY
  #endif
  right_index_middy: homey_right_index_middy {
    compatible = "zmk,behavior-hold-tap";
    flavor = RIGHT_INDEX_HOLDING_TYPE;
    hold-trigger-key-positions = <LEFT_HAND_KEYS THUMB_KEYS>;
    hold-trigger-on-release; // wait for other home row mods
    tapping-term-ms = <RIGHT_INDEX_HOLDING_TIME>;
    quick-tap-ms = <RIGHT_INDEX_REPEAT_DECAY>;
    require-prior-idle-ms = <RIGHT_INDEX_STREAK_DECAY>;
    #binding-cells = <2>;
    bindings = <&kp>, <&kp>;
  };
  right_index_middy_bilateral: homey_right_index_middy_bilateral {
    compatible = "zmk,behavior-hold-tap";
    flavor = RIGHT_INDEX_HOLDING_TYPE;
    hold-trigger-key-positions = <LEFT_HAND_KEYS THUMB_KEYS>;
    hold-trigger-on-release; // wait for other home row mods
    tapping-term-ms = <RIGHT_INDEX_HOLDING_TIME>;
    quick-tap-ms = <RIGHT_INDEX_REPEAT_DECAY>;
    require-prior-idle-ms = <RIGHT_INDEX_STREAK_DECAY>;
    #binding-cells = <2>;
    bindings = <&kp>, <&right_index_tap>;
  };
  #define RightIndexMiddy right_index_middy_bilateral RIGHT_MIDDY_MOD RIGHT_MIDDY_KEY
  #ifndef LEFT_PINKY_INDEX_HOLDING_TYPE
  #define LEFT_PINKY_INDEX_HOLDING_TYPE LEFT_PINKY_CHORD_HOLDING_TYPE
  #endif
  #ifndef LEFT_PINKY_INDEX_HOLDING_TIME
  #define LEFT_PINKY_INDEX_HOLDING_TIME LEFT_PINKY_CHORD_HOLDING_TIME
  #endif
  #ifndef LEFT_PINKY_INDEX_STREAK_DECAY
  #define LEFT_PINKY_INDEX_STREAK_DECAY LEFT_PINKY_CHORD_STREAK_DECAY
  #endif
  #ifndef LEFT_PINKY_INDEX_REPEAT_DECAY
  #define LEFT_PINKY_INDEX_REPEAT_DECAY LEFT_PINKY_CHORD_REPEAT_DECAY
  #endif
  left_pinky_index: homey_left_pinky_index {
    compatible = "zmk,behavior-hold-tap";
    flavor = LEFT_PINKY_HOLDING_TYPE;
    hold-trigger-key-positions = <RIGHT_HAND_KEYS THUMB_KEYS>;
    hold-trigger-on-release; // wait for other home row mods
    tapping-term-ms = <LEFT_PINKY_HOLDING_TIME>;
    quick-tap-ms = <LEFT_PINKY_REPEAT_DECAY>;
    require-prior-idle-ms = <LEFT_PINKY_STREAK_DECAY>;
    #binding-cells = <2>;
    bindings = <&kp>, <&kp>;
  };
  left_pinky_index_bilateral: homey_left_pinky_index_bilateral {
    compatible = "zmk,behavior-hold-tap";
    flavor = LEFT_PINKY_HOLDING_TYPE;
    hold-trigger-key-positions = <RIGHT_HAND_KEYS THUMB_KEYS>;
    hold-trigger-on-release; // wait for other home row mods
    tapping-term-ms = <LEFT_PINKY_HOLDING_TIME>;
    quick-tap-ms = <LEFT_PINKY_REPEAT_DECAY>;
    require-prior-idle-ms = <LEFT_PINKY_STREAK_DECAY>;
    #binding-cells = <2>;
    bindings = <&kp>, <&left_pinky_tap>;
  };
  #define LeftPinkyIndex left_pinky_index_bilateral LEFT_INDEX_MOD LEFT_INDEX_KEY
  #ifndef LEFT_RINGY_INDEX_HOLDING_TYPE
  #define LEFT_RINGY_INDEX_HOLDING_TYPE LEFT_RINGY_CHORD_HOLDING_TYPE
  #endif
  #ifndef LEFT_RINGY_INDEX_HOLDING_TIME
  #define LEFT_RINGY_INDEX_HOLDING_TIME LEFT_RINGY_CHORD_HOLDING_TIME
  #endif
  #ifndef LEFT_RINGY_INDEX_STREAK_DECAY
  #define LEFT_RINGY_INDEX_STREAK_DECAY LEFT_RINGY_CHORD_STREAK_DECAY
  #endif
  #ifndef LEFT_RINGY_INDEX_REPEAT_DECAY
  #define LEFT_RINGY_INDEX_REPEAT_DECAY LEFT_RINGY_CHORD_REPEAT_DECAY
  #endif
  left_ringy_index: homey_left_ringy_index {
    compatible = "zmk,behavior-hold-tap";
    flavor = LEFT_RINGY_HOLDING_TYPE;
    hold-trigger-key-positions = <RIGHT_HAND_KEYS THUMB_KEYS>;
    hold-trigger-on-release; // wait for other home row mods
    tapping-term-ms = <LEFT_RINGY_HOLDING_TIME>;
    quick-tap-ms = <LEFT_RINGY_REPEAT_DECAY>;
    require-prior-idle-ms = <LEFT_RINGY_STREAK_DECAY>;
    #binding-cells = <2>;
    bindings = <&kp>, <&kp>;
  };
  left_ringy_index_bilateral: homey_left_ringy_index_bilateral {
    compatible = "zmk,behavior-hold-tap";
    flavor = LEFT_RINGY_HOLDING_TYPE;
    hold-trigger-key-positions = <RIGHT_HAND_KEYS THUMB_KEYS>;
    hold-trigger-on-release; // wait for other home row mods
    tapping-term-ms = <LEFT_RINGY_HOLDING_TIME>;
    quick-tap-ms = <LEFT_RINGY_REPEAT_DECAY>;
    require-prior-idle-ms = <LEFT_RINGY_STREAK_DECAY>;
    #binding-cells = <2>;
    bindings = <&kp>, <&left_ringy_tap>;
  };
  #define LeftRingyIndex left_ringy_index_bilateral LEFT_INDEX_MOD LEFT_INDEX_KEY
  #ifndef LEFT_MIDDY_INDEX_HOLDING_TYPE
  #define LEFT_MIDDY_INDEX_HOLDING_TYPE LEFT_MIDDY_CHORD_HOLDING_TYPE
  #endif
  #ifndef LEFT_MIDDY_INDEX_HOLDING_TIME
  #define LEFT_MIDDY_INDEX_HOLDING_TIME LEFT_MIDDY_CHORD_HOLDING_TIME
  #endif
  #ifndef LEFT_MIDDY_INDEX_STREAK_DECAY
  #define LEFT_MIDDY_INDEX_STREAK_DECAY LEFT_MIDDY_CHORD_STREAK_DECAY
  #endif
  #ifndef LEFT_MIDDY_INDEX_REPEAT_DECAY
  #define LEFT_MIDDY_INDEX_REPEAT_DECAY LEFT_MIDDY_CHORD_REPEAT_DECAY
  #endif
  left_middy_index: homey_left_middy_index {
    compatible = "zmk,behavior-hold-tap";
    flavor = LEFT_MIDDY_HOLDING_TYPE;
    hold-trigger-key-positions = <RIGHT_HAND_KEYS THUMB_KEYS>;
    hold-trigger-on-release; // wait for other home row mods
    tapping-term-ms = <LEFT_MIDDY_HOLDING_TIME>;
    quick-tap-ms = <LEFT_MIDDY_REPEAT_DECAY>;
    require-prior-idle-ms = <LEFT_MIDDY_STREAK_DECAY>;
    #binding-cells = <2>;
    bindings = <&kp>, <&kp>;
  };
  left_middy_index_bilateral: homey_left_middy_index_bilateral {
    compatible = "zmk,behavior-hold-tap";
    flavor = LEFT_MIDDY_HOLDING_TYPE;
    hold-trigger-key-positions = <RIGHT_HAND_KEYS THUMB_KEYS>;
    hold-trigger-on-release; // wait for other home row mods
    tapping-term-ms = <LEFT_MIDDY_HOLDING_TIME>;
    quick-tap-ms = <LEFT_MIDDY_REPEAT_DECAY>;
    require-prior-idle-ms = <LEFT_MIDDY_STREAK_DECAY>;
    #binding-cells = <2>;
    bindings = <&kp>, <&left_middy_tap>;
  };
  #define LeftMiddyIndex left_middy_index_bilateral LEFT_INDEX_MOD LEFT_INDEX_KEY
  #ifndef RIGHT_PINKY_INDEX_HOLDING_TYPE
  #define RIGHT_PINKY_INDEX_HOLDING_TYPE RIGHT_PINKY_CHORD_HOLDING_TYPE
  #endif
  #ifndef RIGHT_PINKY_INDEX_HOLDING_TIME
  #define RIGHT_PINKY_INDEX_HOLDING_TIME RIGHT_PINKY_CHORD_HOLDING_TIME
  #endif
  #ifndef RIGHT_PINKY_INDEX_STREAK_DECAY
  #define RIGHT_PINKY_INDEX_STREAK_DECAY RIGHT_PINKY_CHORD_STREAK_DECAY
  #endif
  #ifndef RIGHT_PINKY_INDEX_REPEAT_DECAY
  #define RIGHT_PINKY_INDEX_REPEAT_DECAY RIGHT_PINKY_CHORD_REPEAT_DECAY
  #endif
  right_pinky_index: homey_right_pinky_index {
    compatible = "zmk,behavior-hold-tap";
    flavor = RIGHT_PINKY_HOLDING_TYPE;
    hold-trigger-key-positions = <LEFT_HAND_KEYS THUMB_KEYS>;
    hold-trigger-on-release; // wait for other home row mods
    tapping-term-ms = <RIGHT_PINKY_HOLDING_TIME>;
    quick-tap-ms = <RIGHT_PINKY_REPEAT_DECAY>;
    require-prior-idle-ms = <RIGHT_PINKY_STREAK_DECAY>;
    #binding-cells = <2>;
    bindings = <&kp>, <&kp>;
  };
  right_pinky_index_bilateral: homey_right_pinky_index_bilateral {
    compatible = "zmk,behavior-hold-tap";
    flavor = RIGHT_PINKY_HOLDING_TYPE;
    hold-trigger-key-positions = <LEFT_HAND_KEYS THUMB_KEYS>;
    hold-trigger-on-release; // wait for other home row mods
    tapping-term-ms = <RIGHT_PINKY_HOLDING_TIME>;
    quick-tap-ms = <RIGHT_PINKY_REPEAT_DECAY>;
    require-prior-idle-ms = <RIGHT_PINKY_STREAK_DECAY>;
    #binding-cells = <2>;
    bindings = <&kp>, <&right_pinky_tap>;
  };
  #define RightPinkyIndex right_pinky_index_bilateral RIGHT_INDEX_MOD RIGHT_INDEX_KEY
  #ifndef RIGHT_RINGY_INDEX_HOLDING_TYPE
  #define RIGHT_RINGY_INDEX_HOLDING_TYPE RIGHT_RINGY_CHORD_HOLDING_TYPE
  #endif
  #ifndef RIGHT_RINGY_INDEX_HOLDING_TIME
  #define RIGHT_RINGY_INDEX_HOLDING_TIME RIGHT_RINGY_CHORD_HOLDING_TIME
  #endif
  #ifndef RIGHT_RINGY_INDEX_STREAK_DECAY
  #define RIGHT_RINGY_INDEX_STREAK_DECAY RIGHT_RINGY_CHORD_STREAK_DECAY
  #endif
  #ifndef RIGHT_RINGY_INDEX_REPEAT_DECAY
  #define RIGHT_RINGY_INDEX_REPEAT_DECAY RIGHT_RINGY_CHORD_REPEAT_DECAY
  #endif
  right_ringy_index: homey_right_ringy_index {
    compatible = "zmk,behavior-hold-tap";
    flavor = RIGHT_RINGY_HOLDING_TYPE;
    hold-trigger-key-positions = <LEFT_HAND_KEYS THUMB_KEYS>;
    hold-trigger-on-release; // wait for other home row mods
    tapping-term-ms = <RIGHT_RINGY_HOLDING_TIME>;
    quick-tap-ms = <RIGHT_RINGY_REPEAT_DECAY>;
    require-prior-idle-ms = <RIGHT_RINGY_STREAK_DECAY>;
    #binding-cells = <2>;
    bindings = <&kp>, <&kp>;
  };
  right_ringy_index_bilateral: homey_right_ringy_index_bilateral {
    compatible = "zmk,behavior-hold-tap";
    flavor = RIGHT_RINGY_HOLDING_TYPE;
    hold-trigger-key-positions = <LEFT_HAND_KEYS THUMB_KEYS>;
    hold-trigger-on-release; // wait for other home row mods
    tapping-term-ms = <RIGHT_RINGY_HOLDING_TIME>;
    quick-tap-ms = <RIGHT_RINGY_REPEAT_DECAY>;
    require-prior-idle-ms = <RIGHT_RINGY_STREAK_DECAY>;
    #binding-cells = <2>;
    bindings = <&kp>, <&right_ringy_tap>;
  };
  #define RightRingyIndex right_ringy_index_bilateral RIGHT_INDEX_MOD RIGHT_INDEX_KEY
  #ifndef RIGHT_MIDDY_INDEX_HOLDING_TYPE
  #define RIGHT_MIDDY_INDEX_HOLDING_TYPE RIGHT_MIDDY_CHORD_HOLDING_TYPE
  #endif
  #ifndef RIGHT_MIDDY_INDEX_HOLDING_TIME
  #define RIGHT_MIDDY_INDEX_HOLDING_TIME RIGHT_MIDDY_CHORD_HOLDING_TIME
  #endif
  #ifndef RIGHT_MIDDY_INDEX_STREAK_DECAY
  #define RIGHT_MIDDY_INDEX_STREAK_DECAY RIGHT_MIDDY_CHORD_STREAK_DECAY
  #endif
  #ifndef RIGHT_MIDDY_INDEX_REPEAT_DECAY
  #define RIGHT_MIDDY_INDEX_REPEAT_DECAY RIGHT_MIDDY_CHORD_REPEAT_DECAY
  #endif
  right_middy_index: homey_right_middy_index {
    compatible = "zmk,behavior-hold-tap";
    flavor = RIGHT_MIDDY_HOLDING_TYPE;
    hold-trigger-key-positions = <LEFT_HAND_KEYS THUMB_KEYS>;
    hold-trigger-on-release; // wait for other home row mods
    tapping-term-ms = <RIGHT_MIDDY_HOLDING_TIME>;
    quick-tap-ms = <RIGHT_MIDDY_REPEAT_DECAY>;
    require-prior-idle-ms = <RIGHT_MIDDY_STREAK_DECAY>;
    #binding-cells = <2>;
    bindings = <&kp>, <&kp>;
  };
  right_middy_index_bilateral: homey_right_middy_index_bilateral {
    compatible = "zmk,behavior-hold-tap";
    flavor = RIGHT_MIDDY_HOLDING_TYPE;
    hold-trigger-key-positions = <LEFT_HAND_KEYS THUMB_KEYS>;
    hold-trigger-on-release; // wait for other home row mods
    tapping-term-ms = <RIGHT_MIDDY_HOLDING_TIME>;
    quick-tap-ms = <RIGHT_MIDDY_REPEAT_DECAY>;
    require-prior-idle-ms = <RIGHT_MIDDY_STREAK_DECAY>;
    #binding-cells = <2>;
    bindings = <&kp>, <&right_middy_tap>;
  };
  #define RightMiddyIndex right_middy_index_bilateral RIGHT_INDEX_MOD RIGHT_INDEX_KEY

  //
  // Thumb cluster hold-tap keys for Miryoku layers
  //
  thumb: thumb_layer_access {
    compatible = "zmk,behavior-hold-tap";
    flavor = THUMB_HOLDING_TYPE;
    tapping-term-ms = <THUMB_HOLDING_TIME>;
    quick-tap-ms = <THUMB_REPEAT_DECAY>; // enable repeat
    #binding-cells = <2>;
    bindings = <&mo>, <&kp>;
  };
  space: thumb_layer_access_spacebar {
    compatible = "zmk,behavior-hold-tap";
    flavor = SPACE_HOLDING_TYPE;
    tapping-term-ms = <SPACE_HOLDING_TIME>;
    quick-tap-ms = <SPACE_REPEAT_DECAY>; // enable repeat
    #binding-cells = <2>;
    bindings = <&mo>, <&kp>;
    #ifdef SPACE_FORGIVENESS
    retro-tap; // tap on standalone hold
    #endif
  };

  //
  // RGB with mods
  //
  rgb_effect: rgb_effect {
    compatible = "zmk,behavior-mod-morph";
    #binding-cells = <0>;
    bindings = <&rgb_ug RGB_EFF>, <&rgb_ug RGB_EFR>;
    mods = <(MOD_LSFT|MOD_RSFT)>;
  };
  rgb_hue: rgb_hue {
    compatible = "zmk,behavior-mod-morph";
    #binding-cells = <0>;
    bindings = <&rgb_ug RGB_HUI>, <&rgb_ug RGB_HUD>;
    mods = <(MOD_LSFT|MOD_RSFT)>;
  };
  rgb_saturation: rgb_saturation {
    compatible = "zmk,behavior-mod-morph";
    #binding-cells = <0>;
    bindings = <&rgb_ug RGB_SAI>, <&rgb_ug RGB_SAD>;
    mods = <(MOD_LSFT|MOD_RSFT)>;
  };
  rgb_brightness: rgb_brightness {
    compatible = "zmk,behavior-mod-morph";
    #binding-cells = <0>;
    bindings = <&rgb_ug RGB_BRI>, <&rgb_ug RGB_BRD>;
    mods = <(MOD_LSFT|MOD_RSFT)>;
  };
  rgb_speed: rgb_speed {
    compatible = "zmk,behavior-mod-morph";
    #binding-cells = <0>;
    bindings = <&rgb_ug RGB_SPD>, <&rgb_ug RGB_SPI>;
    mods = <(MOD_LSFT|MOD_RSFT)>;
  };

  //////////////////////////////////////////////////////////////////////////
  //
  // ZMK global overrides
  //
  //////////////////////////////////////////////////////////////////////////

  //
  // CapsWord - ported from Pascal Getreuer's extension for QMK
  // - https://zmk.dev/docs/behaviors/caps-word
  // - https://getreuer.info/posts/keyboards/caps-word/index.html
  //
  behavior_caps_word {
    continue-list = <
      UNDERSCORE MINUS
      BSPC DELETE
      N1 N2 N3 N4 N5 N6 N7 N8 N9 N0
    >;
  };

};

macros {
  #define select_all kp _C(A)
  #define select_all_mac kp _C_Mac(A)
};
/*HACK*/};

/*HACK*//{

//////////////////////////////////////////////////////////////////////////
//
// Mouse keys (keyboard mouse control) requires v24.12 firmware or newer:
// override the "HID_POINTING" setting to "y" in Advanced Configuration
// and then select "v24.12" firmware from the drop-down menu located at
// Glove80 Layout Editor > Settings > Advanced Settings > Firmware Version
//
// Alternatively, you can use either PR36 or PR23 beta firmware for this:
// select "community.pr36.mouse-keys" from the drop-down menu located at
// Glove80 Layout Editor > Settings > Advanced Settings > Firmware Version
//
// - https://github.com/moergo-sc/zmk/pull/36
// - https://github.com/moergo-sc/zmk/pull/23
// - https://gist.github.com/krissen/dd27082e7ab0575619c7a31f4d2ec7ae
// - https://github.com/zmkfirmware/zmk/compare/main...urob:zmk:mouse-3.2
// - https://github.com/caksoylar/zmk-config/commit/0020c23c544cd7111013f0114609d1fb90e0e475
// - https://github.com/caksoylar/zmk-config/commit/e35ee2f08788927683df7bbdd7fc73434473886e
//
//////////////////////////////////////////////////////////////////////////

//
// NATURAL_SCROLLING reverses the directionality of the mouse scroll wheel
// to support "natural scrolling" in macOS and other desktop environments.
//

#define MOUSE_SCROLL_UP    SCRL_UP
#define MOUSE_SCROLL_DOWN  SCRL_DOWN
#define MOUSE_SCROLL_LEFT  SCRL_LEFT
#define MOUSE_SCROLL_RIGHT SCRL_RIGHT

//
// MOUSE_MOTION_DELAY defines how long to wait (milliseconds) before starting
// to move the mouse pointer.
//
#ifndef MOUSE_MOTION_DELAY
#define MOUSE_MOTION_DELAY 0
#endif

//
// MOUSE_MOTION_ACCELERATION_EXPONENT sets how the mouse pointer accelerates:
//
// acceleration exponent 0: uniform speed
// acceleration exponent 1: uniform acceleration
// acceleration exponent 2: uniform jerk
//
#ifndef MOUSE_MOTION_ACCELERATION_EXPONENT
#define MOUSE_MOTION_ACCELERATION_EXPONENT 1
#endif

//
// MOUSE_MOTION_TIME_TO_MAXIMUM_SPEED defines how long to wait (milliseconds)
// before the mouse pointer speed is suddenly boosted to the maximum value.
//
#ifndef MOUSE_MOTION_TIME_TO_MAXIMUM_SPEED
#define MOUSE_MOTION_TIME_TO_MAXIMUM_SPEED 300
#endif

//
// MOUSE_MOTION_MAXIMUM_SPEED defines how quickly the mouse pointer can move.
//
#ifndef MOUSE_MOTION_MAXIMUM_SPEED
#define MOUSE_MOTION_MAXIMUM_SPEED 600
#endif

//
// MOUSE_SCROLL_DELAY defines how long to wait (milliseconds) before starting
// to move the mouse pointer.
//
#ifndef MOUSE_SCROLL_DELAY
#define MOUSE_SCROLL_DELAY 0
#endif

//
// MOUSE_SCROLL_ACCELERATION_EXPONENT sets how the mouse pointer accelerates:
//
// acceleration exponent 0: uniform speed
// acceleration exponent 1: uniform acceleration
// acceleration exponent 2: uniform jerk
//
#ifndef MOUSE_SCROLL_ACCELERATION_EXPONENT
#define MOUSE_SCROLL_ACCELERATION_EXPONENT 0
#endif

//
// MOUSE_SCROLL_TIME_TO_MAXIMUM_SPEED defines how long to wait (milliseconds)
// before the mouse pointer speed is suddenly boosted to the maximum value.
//
#ifndef MOUSE_SCROLL_TIME_TO_MAXIMUM_SPEED
#define MOUSE_SCROLL_TIME_TO_MAXIMUM_SPEED 300
#endif

//
// MOUSE_SCROLL_MAXIMUM_SPEED defines how quickly the mouse wheel can scroll.
//
#ifndef MOUSE_SCROLL_MAXIMUM_SPEED
#define MOUSE_SCROLL_MAXIMUM_SPEED 10
#endif

/*HACK*/};

// ==== MOUSE-KEY <section begins> ====
#include <dt-bindings/zmk/pointing.h>
&mmv {
  delay-ms = <MOUSE_MOTION_DELAY>;
  acceleration-exponent = <MOUSE_MOTION_ACCELERATION_EXPONENT>;
  time-to-max-speed-ms = <MOUSE_MOTION_TIME_TO_MAXIMUM_SPEED>;
};
&msc {
  delay-ms = <MOUSE_SCROLL_DELAY>;
  acceleration-exponent = <MOUSE_SCROLL_ACCELERATION_EXPONENT>;
  time-to-max-speed-ms = <MOUSE_SCROLL_TIME_TO_MAXIMUM_SPEED>;
};
// ==== MOUSE-KEY <section ends> =====

/* Automatically generated keymap */
/ {
    keymap {
        compatible = "zmk,keymap";

        layer_QWERTY_Mac {
            bindings = <
            &kp EQUAL                                &kp N1                            &kp N2                            &kp N3                            &kp N4    &kp N5    &kp N6                             &kp N7                             &kp N8                             &kp N9                                    &kp N0             &kp MINUS
            &kp GRAVE                                 &kp Q                             &kp W                             &kp E                             &kp R     &kp T     &kp Y                              &kp U                              &kp I                              &kp O                                     &kp P              &kp BSLH
             &kp CAPS      &LeftPinky (A, LAYER_QWERTY_Mac)  &LeftRingy (S, LAYER_QWERTY_Mac)  &LeftMiddy (D, LAYER_QWERTY_Mac)  &LeftIndex (F, LAYER_QWERTY_Mac)     &kp G     &kp H  &RightIndex (J, LAYER_QWERTY_Mac)  &RightMiddy (K, LAYER_QWERTY_Mac)  &RightRingy (L, LAYER_QWERTY_Mac)      &RightPinky (SEMI, LAYER_QWERTY_Mac)               &kp SQT
 &magic LAYER_Magic 0             &thumb LAYER_Button_Mac Z                             &kp X                             &kp C                             &kp V     &kp B     &kp N                              &kp M                          &kp COMMA                            &kp DOT              &thumb LAYER_Button_Mac FSLH  &magic LAYER_Magic 0
                                                                                     &kp LEFT                         &kp RIGHT           &thumb LAYER_System ESC                           &thumb LAYER_Function DELETE                             &kp UP                           &kp DOWN
                                                                                                      &space LAYER_Cursor SPACE            &thumb LAYER_Mouse TAB  &kp LGUI  &kp RGUI          &thumb LAYER_Symbol ENTER           &thumb LAYER_Number BSPC
            >;
        };

        layer_QWERTY {
            bindings = <
            &kp EQUAL                        &kp N1                        &kp N2                        &kp N3                        &kp N4    &kp N5    &kp N6                         &kp N7                         &kp N8                         &kp N9                            &kp N0             &kp MINUS
            &kp GRAVE                         &kp Q                         &kp W                         &kp E                         &kp R     &kp T     &kp Y                          &kp U                          &kp I                          &kp O                             &kp P              &kp BSLH
             &kp CAPS  &LeftPinky (A, LAYER_QWERTY)  &LeftRingy (S, LAYER_QWERTY)  &LeftMiddy (D, LAYER_QWERTY)  &LeftIndex (F, LAYER_QWERTY)     &kp G     &kp H  &RightIndex (J, LAYER_QWERTY)  &RightMiddy (K, LAYER_QWERTY)  &RightRingy (L, LAYER_QWERTY)  &RightPinky (SEMI, LAYER_QWERTY)               &kp SQT
 &magic LAYER_Magic 0         &thumb LAYER_Button Z                         &kp X                         &kp C                         &kp V     &kp B     &kp N                          &kp M                      &kp COMMA                        &kp DOT          &thumb LAYER_Button FSLH  &magic LAYER_Magic 0
                                                                         &kp LEFT                     &kp RIGHT       &thumb LAYER_System ESC                       &thumb LAYER_Function DELETE                         &kp UP                       &kp DOWN
                                                                                      &space LAYER_Cursor SPACE        &thumb LAYER_Mouse TAB  &kp LGUI  &kp RGUI      &thumb LAYER_Symbol ENTER       &thumb LAYER_Number BSPC
            >;
        };

        layer_Typing {
            bindings = <
 &trans              &trans              &trans              &trans              &trans             &trans             &trans               &trans               &trans               &trans               &trans  &trans
 &trans              &trans              &trans              &trans              &trans             &trans             &trans               &trans               &trans               &trans               &trans  &trans
 &trans  &kp LEFT_PINKY_KEY  &kp LEFT_RINGY_KEY  &kp LEFT_MIDDY_KEY  &kp LEFT_INDEX_KEY             &trans             &trans  &kp RIGHT_INDEX_KEY  &kp RIGHT_MIDDY_KEY  &kp RIGHT_RINGY_KEY  &kp RIGHT_PINKY_KEY  &trans
 &trans     &kp KEY_LH_C5R4              &trans              &trans              &trans             &trans             &trans               &trans               &trans               &trans      &kp KEY_RH_C5R4  &trans
                                         &trans              &trans     &kp KEY_LH_C2R5                                            &kp KEY_RH_C2R5               &trans               &trans
                                                      &kp KEY_LH_T1       &kp KEY_LH_T2  &tog LAYER_Typing  &tog LAYER_Typing        &kp KEY_RH_T2        &kp KEY_RH_T1
            >;
        };

        layer_Gaming {
            bindings = <
   &kp N5  &kp GRAVE  &kp N1     &kp N2    &kp N3  &kp N4              &kp N6   &kp N7     &kp N8    &kp N9    &kp N0  &kp MINUS
    &kp T    &kp TAB   &kp Q      &kp W     &kp E   &kp R               &kp Y    &kp U      &kp I     &kp O     &kp P   &kp BSLH
    &kp G  &kp LSHFT   &kp A      &kp S     &kp D   &kp F               &kp H    &kp J      &kp K     &kp L  &kp SEMI    &kp SQT
 &kp CAPS  &kp LCTRL   &kp Z      &kp X     &kp C   &kp V               &kp N    &kp M  &kp COMMA   &kp DOT  &kp FSLH  &kp RSHFT
                       &kp N      &kp M   &kp ESC                              &kp DEL     &kp UP  &kp DOWN
                              &kp SPACE  &kp LALT   &kp B   &tog LAYER_Gaming  &kp RET   &kp BSPC
            >;
        };

        layer_Dota {
            bindings = <
 &kp GRAVE  &kp F1  &kp F2     &kp F3    &kp F4  &kp F5           &kp N6   &kp N7     &kp N8    &kp N9    &kp N0  &kp MINUS
   &kp TAB  &kp N1  &kp N2     &kp N3    &kp N4  &kp N5            &kp Y    &kp U      &kp I     &kp O     &kp P   &kp BSLH
 &kp LSHFT   &kp Q   &kp W      &kp E     &kp R   &kp T            &kp H    &kp J      &kp K     &kp L  &kp SEMI    &kp SQT
  &kp CAPS   &kp A   &kp S      &kp D     &kp F   &kp G            &kp N    &kp M  &kp COMMA   &kp DOT  &kp FSLH  &kp RSHFT
                     &kp C      &kp V   &kp ESC                           &kp DEL     &kp UP  &kp DOWN
                            &kp SPACE  &kp LALT   &kp X  &tog LAYER_Dota  &kp RET   &kp BSPC
            >;
        };

        layer_LeftPinky {
            bindings = <
 &left_pinky_tap KEY_LH_C6R1  &left_pinky_tap KEY_LH_C5R1  &left_pinky_tap KEY_LH_C4R1  &left_pinky_tap KEY_LH_C3R1  &left_pinky_tap KEY_LH_C2R1  &left_pinky_tap KEY_LH_C1R1  &trans               &trans               &trans               &trans               &trans  &trans
 &left_pinky_tap KEY_LH_C6R2  &left_pinky_tap KEY_LH_C5R2  &left_pinky_tap KEY_LH_C4R2  &left_pinky_tap KEY_LH_C3R2  &left_pinky_tap KEY_LH_C2R2  &left_pinky_tap KEY_LH_C1R2  &trans               &trans               &trans               &trans               &trans  &trans
 &left_pinky_tap KEY_LH_C6R3                        &none              &LeftPinkyRingy              &LeftPinkyMiddy              &LeftPinkyIndex  &left_pinky_tap KEY_LH_C1R3  &trans  &kp RIGHT_INDEX_KEY  &kp RIGHT_MIDDY_KEY  &kp RIGHT_RINGY_KEY  &kp RIGHT_PINKY_KEY  &trans
 &left_pinky_tap KEY_LH_C6R4  &left_pinky_tap KEY_LH_C5R4  &left_pinky_tap KEY_LH_C4R4  &left_pinky_tap KEY_LH_C3R4  &left_pinky_tap KEY_LH_C2R4  &left_pinky_tap KEY_LH_C1R4  &trans               &trans               &trans               &trans               &trans  &trans
                                                           &left_pinky_tap KEY_LH_C4R5  &left_pinky_tap KEY_LH_C3R5                       &trans                                                    &trans               &trans               &trans
                                                                                                             &trans                       &trans    &left_pinky_tap KEY_LH_T3  &trans               &trans               &trans
            >;
        };

        layer_LeftRingy {
            bindings = <
 &left_ringy_tap KEY_LH_C6R1  &left_ringy_tap KEY_LH_C5R1  &left_ringy_tap KEY_LH_C4R1  &left_ringy_tap KEY_LH_C3R1  &left_ringy_tap KEY_LH_C2R1  &left_ringy_tap KEY_LH_C1R1  &trans               &trans               &trans               &trans               &trans  &trans
 &left_ringy_tap KEY_LH_C6R2  &left_ringy_tap KEY_LH_C5R2  &left_ringy_tap KEY_LH_C4R2  &left_ringy_tap KEY_LH_C3R2  &left_ringy_tap KEY_LH_C2R2  &left_ringy_tap KEY_LH_C1R2  &trans               &trans               &trans               &trans               &trans  &trans
 &left_ringy_tap KEY_LH_C6R3              &LeftRingyPinky                        &none              &LeftRingyMiddy              &LeftRingyIndex  &left_ringy_tap KEY_LH_C1R3  &trans  &kp RIGHT_INDEX_KEY  &kp RIGHT_MIDDY_KEY  &kp RIGHT_RINGY_KEY  &kp RIGHT_PINKY_KEY  &trans
 &left_ringy_tap KEY_LH_C6R4  &left_ringy_tap KEY_LH_C5R4  &left_ringy_tap KEY_LH_C4R4  &left_ringy_tap KEY_LH_C3R4  &left_ringy_tap KEY_LH_C2R4  &left_ringy_tap KEY_LH_C1R4  &trans               &trans               &trans               &trans               &trans  &trans
                                                           &left_ringy_tap KEY_LH_C4R5  &left_ringy_tap KEY_LH_C3R5                       &trans                                                    &trans               &trans               &trans
                                                                                                             &trans                       &trans    &left_ringy_tap KEY_LH_T3  &trans               &trans               &trans
            >;
        };

        layer_LeftMiddy {
            bindings = <
 &left_middy_tap KEY_LH_C6R1  &left_middy_tap KEY_LH_C5R1  &left_middy_tap KEY_LH_C4R1  &left_middy_tap KEY_LH_C3R1  &left_middy_tap KEY_LH_C2R1  &left_middy_tap KEY_LH_C1R1  &trans               &trans               &trans               &trans               &trans  &trans
 &left_middy_tap KEY_LH_C6R2  &left_middy_tap KEY_LH_C5R2  &left_middy_tap KEY_LH_C4R2  &left_middy_tap KEY_LH_C3R2  &left_middy_tap KEY_LH_C2R2  &left_middy_tap KEY_LH_C1R2  &trans               &trans               &trans               &trans               &trans  &trans
 &left_middy_tap KEY_LH_C6R3              &LeftMiddyPinky              &LeftMiddyRingy                        &none              &LeftMiddyIndex  &left_middy_tap KEY_LH_C1R3  &trans  &kp RIGHT_INDEX_KEY  &kp RIGHT_MIDDY_KEY  &kp RIGHT_RINGY_KEY  &kp RIGHT_PINKY_KEY  &trans
 &left_middy_tap KEY_LH_C6R4  &left_middy_tap KEY_LH_C5R4  &left_middy_tap KEY_LH_C4R4  &left_middy_tap KEY_LH_C3R4  &left_middy_tap KEY_LH_C2R4  &left_middy_tap KEY_LH_C1R4  &trans               &trans               &trans               &trans               &trans  &trans
                                                           &left_middy_tap KEY_LH_C4R5  &left_middy_tap KEY_LH_C3R5                       &trans                                                    &trans               &trans               &trans
                                                                                                             &trans                       &trans    &left_middy_tap KEY_LH_T3  &trans               &trans               &trans
            >;
        };

        layer_LeftIndex {
            bindings = <
 &left_index_tap KEY_LH_C6R1  &left_index_tap KEY_LH_C5R1  &left_index_tap KEY_LH_C4R1  &left_index_tap KEY_LH_C3R1  &left_index_tap KEY_LH_C2R1  &left_index_tap KEY_LH_C1R1  &trans               &trans               &trans               &trans               &trans  &trans
 &left_index_tap KEY_LH_C6R2  &left_index_tap KEY_LH_C5R2  &left_index_tap KEY_LH_C4R2  &left_index_tap KEY_LH_C3R2  &left_index_tap KEY_LH_C2R2  &left_index_tap KEY_LH_C1R2  &trans               &trans               &trans               &trans               &trans  &trans
 &left_index_tap KEY_LH_C6R3              &LeftIndexPinky              &LeftIndexRingy              &LeftIndexMiddy                        &none  &left_index_tap KEY_LH_C1R3  &trans  &kp RIGHT_INDEX_KEY  &kp RIGHT_MIDDY_KEY  &kp RIGHT_RINGY_KEY  &kp RIGHT_PINKY_KEY  &trans
 &left_index_tap KEY_LH_C6R4  &left_index_tap KEY_LH_C5R4  &left_index_tap KEY_LH_C4R4  &left_index_tap KEY_LH_C3R4  &left_index_tap KEY_LH_C2R4  &left_index_tap KEY_LH_C1R4  &trans               &trans               &trans               &trans               &trans  &trans
                                                           &left_index_tap KEY_LH_C4R5  &left_index_tap KEY_LH_C3R5                       &trans                                                    &trans               &trans               &trans
                                                                                                             &trans                       &trans    &left_index_tap KEY_LH_T3  &trans               &trans               &trans
            >;
        };

        layer_RightPinky {
            bindings = <
 &trans              &trans              &trans              &trans              &trans  &trans  &right_pinky_tap KEY_RH_C1R1  &right_pinky_tap KEY_RH_C2R1  &right_pinky_tap KEY_RH_C3R1  &right_pinky_tap KEY_RH_C4R1  &right_pinky_tap KEY_RH_C5R1  &right_pinky_tap KEY_RH_C6R1
 &trans              &trans              &trans              &trans              &trans  &trans  &right_pinky_tap KEY_RH_C1R2  &right_pinky_tap KEY_RH_C2R2  &right_pinky_tap KEY_RH_C3R2  &right_pinky_tap KEY_RH_C4R2  &right_pinky_tap KEY_RH_C5R2  &right_pinky_tap KEY_RH_C6R2
 &trans  &kp LEFT_PINKY_KEY  &kp LEFT_RINGY_KEY  &kp LEFT_MIDDY_KEY  &kp LEFT_INDEX_KEY  &trans  &right_pinky_tap KEY_RH_C1R3              &RightPinkyIndex              &RightPinkyMiddy              &RightPinkyRingy                         &none  &right_pinky_tap KEY_RH_C6R3
 &trans              &trans              &trans              &trans              &trans  &trans  &right_pinky_tap KEY_RH_C1R4  &right_pinky_tap KEY_RH_C2R4  &right_pinky_tap KEY_RH_C3R4  &right_pinky_tap KEY_RH_C4R4  &right_pinky_tap KEY_RH_C5R4  &right_pinky_tap KEY_RH_C6R4
                                         &trans              &trans              &trans                                                              &trans  &right_pinky_tap KEY_RH_C3R5  &right_pinky_tap KEY_RH_C4R5
                                                             &trans              &trans  &trans    &right_pinky_tap KEY_RH_T3                        &trans                        &trans
            >;
        };

        layer_RightRingy {
            bindings = <
 &trans              &trans              &trans              &trans              &trans  &trans  &right_ringy_tap KEY_RH_C1R1  &right_ringy_tap KEY_RH_C2R1  &right_ringy_tap KEY_RH_C3R1  &right_ringy_tap KEY_RH_C4R1  &right_ringy_tap KEY_RH_C5R1  &right_ringy_tap KEY_RH_C6R1
 &trans              &trans              &trans              &trans              &trans  &trans  &right_ringy_tap KEY_RH_C1R2  &right_ringy_tap KEY_RH_C2R2  &right_ringy_tap KEY_RH_C3R2  &right_ringy_tap KEY_RH_C4R2  &right_ringy_tap KEY_RH_C5R2  &right_ringy_tap KEY_RH_C6R2
 &trans  &kp LEFT_PINKY_KEY  &kp LEFT_RINGY_KEY  &kp LEFT_MIDDY_KEY  &kp LEFT_INDEX_KEY  &trans  &right_ringy_tap KEY_RH_C1R3              &RightRingyIndex              &RightRingyMiddy                         &none              &RightRingyPinky  &right_ringy_tap KEY_RH_C6R3
 &trans              &trans              &trans              &trans              &trans  &trans  &right_ringy_tap KEY_RH_C1R4  &right_ringy_tap KEY_RH_C2R4  &right_ringy_tap KEY_RH_C3R4  &right_ringy_tap KEY_RH_C4R4  &right_ringy_tap KEY_RH_C5R4  &right_ringy_tap KEY_RH_C6R4
                                         &trans              &trans              &trans                                                              &trans  &right_ringy_tap KEY_RH_C3R5  &right_ringy_tap KEY_RH_C4R5
                                                             &trans              &trans  &trans    &right_ringy_tap KEY_RH_T3                        &trans                        &trans
            >;
        };

        layer_RightMiddy {
            bindings = <
 &trans              &trans              &trans              &trans              &trans  &trans  &right_middy_tap KEY_RH_C1R1  &right_middy_tap KEY_RH_C2R1  &right_middy_tap KEY_RH_C3R1  &right_middy_tap KEY_RH_C4R1  &right_middy_tap KEY_RH_C5R1  &right_middy_tap KEY_RH_C6R1
 &trans              &trans              &trans              &trans              &trans  &trans  &right_middy_tap KEY_RH_C1R2  &right_middy_tap KEY_RH_C2R2  &right_middy_tap KEY_RH_C3R2  &right_middy_tap KEY_RH_C4R2  &right_middy_tap KEY_RH_C5R2  &right_middy_tap KEY_RH_C6R2
 &trans  &kp LEFT_PINKY_KEY  &kp LEFT_RINGY_KEY  &kp LEFT_MIDDY_KEY  &kp LEFT_INDEX_KEY  &trans  &right_middy_tap KEY_RH_C1R3              &RightMiddyIndex                         &none              &RightMiddyRingy              &RightMiddyPinky  &right_middy_tap KEY_RH_C6R3
 &trans              &trans              &trans              &trans              &trans  &trans  &right_middy_tap KEY_RH_C1R4  &right_middy_tap KEY_RH_C2R4  &right_middy_tap KEY_RH_C3R4  &right_middy_tap KEY_RH_C4R4  &right_middy_tap KEY_RH_C5R4  &right_middy_tap KEY_RH_C6R4
                                         &trans              &trans              &trans                                                              &trans  &right_middy_tap KEY_RH_C3R5  &right_middy_tap KEY_RH_C4R5
                                                             &trans              &trans  &trans    &right_middy_tap KEY_RH_T3                        &trans                        &trans
            >;
        };

        layer_RightIndex {
            bindings = <
 &trans              &trans              &trans              &trans              &trans  &trans  &right_index_tap KEY_RH_C1R1  &right_index_tap KEY_RH_C2R1  &right_index_tap KEY_RH_C3R1  &right_index_tap KEY_RH_C4R1  &right_index_tap KEY_RH_C5R1  &right_index_tap KEY_RH_C6R1
 &trans              &trans              &trans              &trans              &trans  &trans  &right_index_tap KEY_RH_C1R2  &right_index_tap KEY_RH_C2R2  &right_index_tap KEY_RH_C3R2  &right_index_tap KEY_RH_C4R2  &right_index_tap KEY_RH_C5R2  &right_index_tap KEY_RH_C6R2
 &trans  &kp LEFT_PINKY_KEY  &kp LEFT_RINGY_KEY  &kp LEFT_MIDDY_KEY  &kp LEFT_INDEX_KEY  &trans  &right_index_tap KEY_RH_C1R3                         &none              &RightIndexMiddy              &RightIndexRingy              &RightIndexPinky  &right_index_tap KEY_RH_C6R3
 &trans              &trans              &trans              &trans              &trans  &trans  &right_index_tap KEY_RH_C1R4  &right_index_tap KEY_RH_C2R4  &right_index_tap KEY_RH_C3R4  &right_index_tap KEY_RH_C4R4  &right_index_tap KEY_RH_C5R4  &right_index_tap KEY_RH_C6R4
                                         &trans              &trans              &trans                                                              &trans  &right_index_tap KEY_RH_C3R5  &right_index_tap KEY_RH_C4R5
                                                             &trans              &trans  &trans    &right_index_tap KEY_RH_T3                        &trans                        &trans
            >;
        };

        layer_System {
            bindings = <
 &none               &none               &none                &none               &none   &none                 &none         &none            &none            &none            &none   &none
 &none         &bootloader   &tog LAYER_Typing                &to 1               &to 0   &studio_unlock  &rgb_effect      &rgb_hue  &rgb_saturation  &rgb_brightness  &rgb_ug RGB_TOG   &none
 &none  &kp LEFT_PINKY_MOD  &kp LEFT_RINGY_MOD   &kp LEFT_MIDDY_MOD  &kp LEFT_INDEX_MOD   &none            &kp C_PREV  &kp C_VOL_DN     &kp C_VOL_UP       &kp C_NEXT       &rgb_speed   &none
 &none      &kp LS(DELETE)          &kp DELETE  &tog LAYER_Function   &tog LAYER_System   &none            &bt BT_CLR         &bt_0            &bt_1            &bt_2     &out OUT_TOG   &none
                                         &none                &none               &none                                  &kp C_MUTE            &none            &none
                                                              &none               &none   &none                 &none    &kp C_STOP         &kp C_PP
            >;
        };

        layer_Cursor {
            bindings = <
 &none               &none               &none               &none               &none   &none     &none      &none      &none      &none      &none   &none
 &none               &none   &tog LAYER_Typing               &none               &to 0   &none     &none      &none      &none      &none      &none   &none
 &none  &kp LEFT_PINKY_MOD  &kp LEFT_RINGY_MOD  &kp LEFT_MIDDY_MOD  &kp LEFT_INDEX_MOD   &none  &kp LEFT   &kp DOWN     &kp UP  &kp RIGHT   &kp CAPS   &none
 &none      &kp LS(DELETE)          &kp DELETE   &tog LAYER_Number   &tog LAYER_Cursor   &none  &kp HOME  &kp PG_DN  &kp PG_UP    &kp END    &kp INS   &none
                                         &none               &none               &none                      &kp DEL      &none      &none
                                                             &none               &none   &none     &none    &kp RET   &kp BSPC
            >;
        };

        layer_Mouse {
            bindings = <
 &none               &none               &none               &none               &none   &none                   &none                   &none                 &none                    &none      &none   &none
 &none               &none   &tog LAYER_Typing   &tog LAYER_Gaming               &to 0   &none                   &none                   &none                 &none                    &none      &none   &none
 &none  &kp LEFT_PINKY_MOD  &kp LEFT_RINGY_MOD  &kp LEFT_MIDDY_MOD  &kp LEFT_INDEX_MOD   &none          &mmv MOVE_LEFT          &mmv MOVE_DOWN          &mmv MOVE_UP          &mmv MOVE_RIGHT   &mkp MB4   &none
 &none      &kp LS(DELETE)          &kp DELETE   &tog LAYER_Symbol    &tog LAYER_Mouse   &none  &msc MOUSE_SCROLL_LEFT  &msc MOUSE_SCROLL_DOWN  &msc MOUSE_SCROLL_UP  &msc MOUSE_SCROLL_RIGHT   &mkp MB5   &none
                                         &none               &none               &none                                               &mkp MCLK                 &none                    &none
                                                             &none               &none   &none                   &none               &mkp RCLK             &mkp LCLK
            >;
        };

        layer_Symbol {
            bindings = <
 &none          &none       &none         &none       &none          &none  &none                &none                &none                &none                &none   &none
 &none   &kp LS(LBKT)  &kp LS(N7)    &kp LS(N8)  &kp LS(N9)   &kp LS(RBKT)  &none                &to 0      &tog LAYER_Dota    &tog LAYER_Typing                &none   &none
 &none    &kp LS(SQT)  &kp LS(N4)    &kp LS(N5)  &kp LS(N6)  &kp LS(EQUAL)  &none  &kp RIGHT_INDEX_MOD  &kp RIGHT_MIDDY_MOD  &kp RIGHT_RINGY_MOD  &kp RIGHT_PINKY_MOD   &none
 &none  &kp LS(GRAVE)  &kp LS(N1)    &kp LS(N2)  &kp LS(N3)   &kp LS(BSLH)  &none    &tog LAYER_Symbol     &tog LAYER_Mouse           &kp DELETE       &kp LS(DELETE)   &none
                                          &none       &none   &kp LS(FSLH)                                            &none                &none                &none
                                                 &kp LS(N0)  &kp LS(MINUS)  &none                &none                &none                &none
            >;
        };

        layer_Number {
            bindings = <
 &none      &none   &none     &none      &none      &none  &none                &none                &none                &none                &none   &none
 &none   &kp LBKT  &kp N7    &kp N8     &kp N9   &kp RBKT  &none                &to 0                &none    &tog LAYER_Typing                &none   &none
 &none    &kp SQT  &kp N4    &kp N5     &kp N6  &kp EQUAL  &none  &kp RIGHT_INDEX_MOD  &kp RIGHT_MIDDY_MOD  &kp RIGHT_RINGY_MOD  &kp RIGHT_PINKY_MOD   &none
 &none  &kp GRAVE  &kp N1    &kp N2     &kp N3   &kp BSLH  &none    &tog LAYER_Number    &tog LAYER_Cursor           &kp DELETE       &kp LS(DELETE)   &none
                              &none      &none   &kp FSLH                                            &none                &none                &none
                                        &kp N0  &kp MINUS  &none                &none                &none                &none
            >;
        };

        layer_Function {
            bindings = <
 &none    &none   &none      &none      &none            &none           &none                &none                &none                &none                &none   &none
 &none  &kp F12  &kp F7     &kp F8     &kp F9        &kp PSCRN  &studio_unlock                &to 0                &to 1    &tog LAYER_Typing          &bootloader   &none
 &none  &kp F11  &kp F4     &kp F5     &kp F6         &kp SLCK           &none  &kp RIGHT_INDEX_MOD  &kp RIGHT_MIDDY_MOD  &kp RIGHT_RINGY_MOD  &kp RIGHT_PINKY_MOD   &none
 &none  &kp F10  &kp F1     &kp F2     &kp F3  &kp PAUSE_BREAK           &none  &tog LAYER_Function    &tog LAYER_System           &kp DELETE       &kp LS(DELETE)   &none
                             &none      &none        &kp K_APP                                                     &none                &none                &none
                                    &kp SPACE          &kp TAB           &none                &none                &none                &none
            >;
        };

        layer_Button {
            bindings = <
 &none               &none               &none               &none               &none        &none        &none                &none                &none                &none                &none   &none
 &none               &none           &kp PSCRN           &kp _FIND             &kp RET  &select_all  &select_all              &kp RET            &kp _FIND            &kp PSCRN                &none   &none
 &none  &kp LEFT_PINKY_MOD  &kp LEFT_RINGY_MOD  &kp LEFT_MIDDY_MOD  &kp LEFT_INDEX_MOD    &kp _UNDO    &kp _UNDO  &kp RIGHT_INDEX_MOD  &kp RIGHT_MIDDY_MOD  &kp RIGHT_RINGY_MOD  &kp RIGHT_PINKY_MOD   &none
 &none           &kp _UNDO            &kp _CUT           &kp _COPY          &kp _PASTE    &kp _REDO    &kp _REDO           &kp _PASTE            &kp _COPY             &kp _CUT            &kp _UNDO   &none
                                         &none               &none   &tog LAYER_System                              &tog LAYER_Symbol                &none                &none
                                                 &tog LAYER_Cursor    &tog LAYER_Mouse        &none        &none    &tog LAYER_Number  &tog LAYER_Function
            >;
        };

        layer_Button_Mac {
            bindings = <
 &none               &none               &none               &none               &none            &none            &none                &none                &none                &none                &none   &none
 &none               &none      &kp _PSCRN_Mac       &kp _FIND_Mac             &kp RET  &select_all_mac  &select_all_mac              &kp RET        &kp _FIND_Mac       &kp _PSCRN_Mac                &none   &none
 &none  &kp LEFT_PINKY_MOD  &kp LEFT_RINGY_MOD  &kp LEFT_MIDDY_MOD  &kp LEFT_INDEX_MOD    &kp _UNDO_Mac    &kp _UNDO_Mac  &kp RIGHT_INDEX_MOD  &kp RIGHT_MIDDY_MOD  &kp RIGHT_RINGY_MOD  &kp RIGHT_PINKY_MOD   &none
 &none       &kp _UNDO_Mac        &kp _CUT_Mac       &kp _COPY_Mac      &kp _PASTE_Mac    &kp _REDO_Mac    &kp _REDO_Mac       &kp _PASTE_Mac        &kp _COPY_Mac         &kp _CUT_Mac        &kp _UNDO_Mac   &none
                                         &none               &none   &tog LAYER_System                                      &tog LAYER_Symbol                &none                &none
                                                 &tog LAYER_Cursor    &tog LAYER_Mouse            &none            &none    &tog LAYER_Number  &tog LAYER_Function
            >;
        };

        layer_Magic {
            bindings = <
       &to 0            &to 1            &to 2            &to 3            &to 4       &bt BT_CLR  &none  &none  &none  &none  &none  &bt BT_CLR_ALL
 &bootloader  &rgb_ug RGB_SPI  &rgb_ug RGB_SAI  &rgb_ug RGB_HUI  &rgb_ug RGB_BRI  &rgb_ug RGB_TOG  &none  &none  &none  &none  &none     &bootloader
  &sys_reset  &rgb_ug RGB_SPD  &rgb_ug RGB_SAD  &rgb_ug RGB_HUD  &rgb_ug RGB_BRD  &rgb_ug RGB_EFF  &none  &none  &none  &none  &none      &sys_reset
       &none            &bt_0            &bt_1            &bt_2            &bt_3            &none  &none  &none  &none  &none  &none           &none
                                  &out OUT_USB            &none            &none                          &none  &none  &none
                                                          &none            &none            &none  &none  &none  &none
            >;
        };
    };
};

&cirque_rh_listener {
    input-processors = <&zip_xy_scaler 2 1>;
    layer_Mouse {
        layers = <LAYER_Mouse>;
        input-processors = <&zip_xy_scaler 4 1>;
    };
};

&cirque_lh_listener {
    input-processors = <&zip_xy_to_scroll_mapper>, <&zip_click_to_right_click_mapper>;
};
